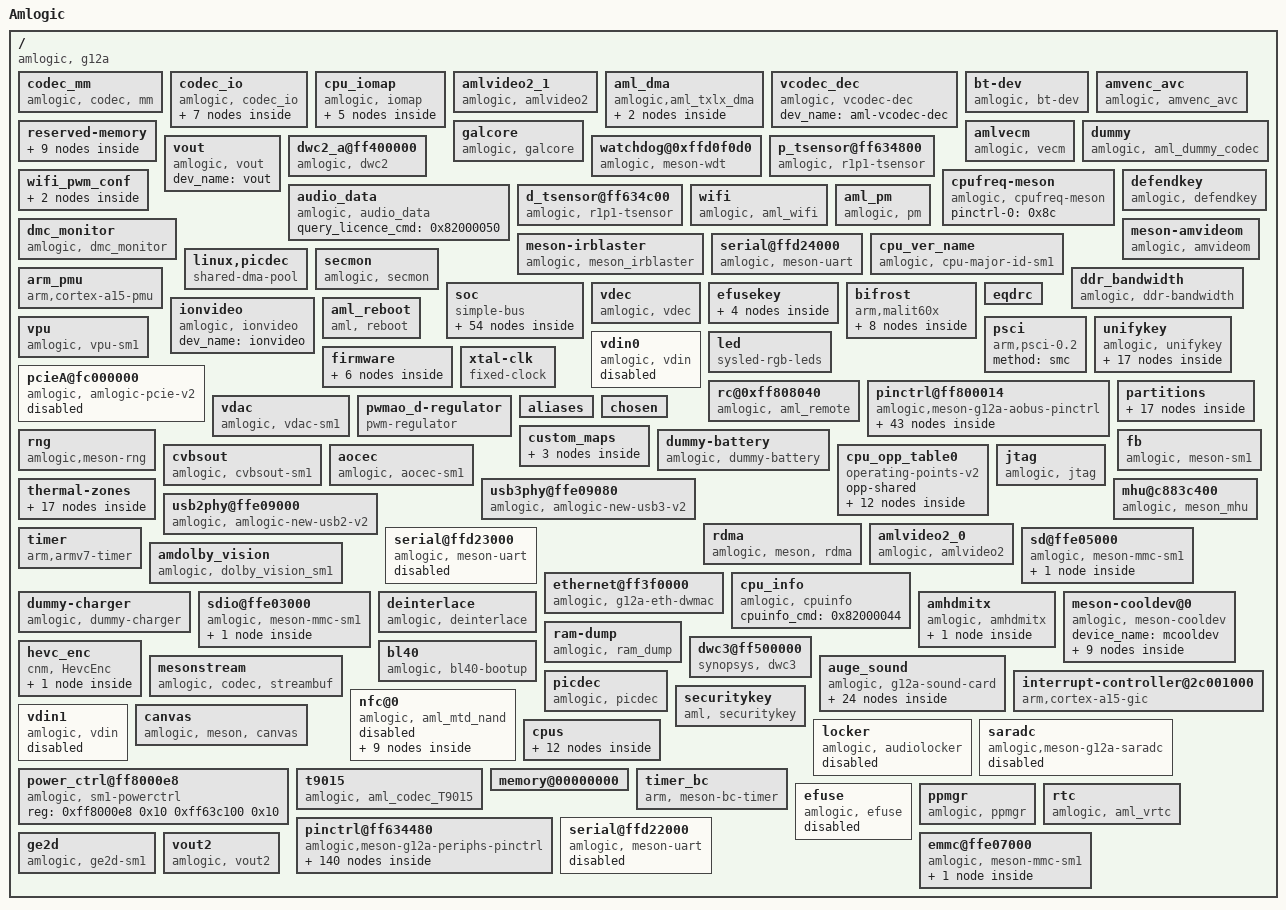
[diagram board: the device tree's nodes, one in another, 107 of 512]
<stdout>: Warning (unit_address_vs_reg): /codec_io/io_efuse_base: node has a reg or ranges property, but no unit name
<stdout>: Warning (unit_address_vs_reg): /codec_io/io_cbus_base: node has a reg or ranges property, but no unit name
<stdout>: Warning (unit_address_vs_reg): /codec_io/io_dmc_base: node has a reg or ranges property, but no unit name
<stdout>: Warning (unit_address_vs_reg): /codec_io/io_vcbus_base: node has a reg or ranges property, but no unit name
<stdout>: Warning (unit_address_vs_reg): /codec_io/io_hiubus_base: node has a reg or ranges property, but no unit name
<stdout>: Warning (unit_address_vs_reg): /codec_io/io_aobus_base: node has a reg or ranges property, but no unit name
<stdout>: Warning (unit_address_vs_reg): /codec_io/io_dos_base: node has a reg or ranges property, but no unit name
<stdout>: Warning (unit_address_vs_reg): /cpu_iomap/io_apb_base: node has a reg or ranges property, but no unit name
<stdout>: Warning (unit_address_vs_reg): /cpu_iomap/io_cbus_base: node has a reg or ranges property, but no unit name
<stdout>: Warning (unit_address_vs_reg): /cpu_iomap/io_vapb_base: node has a reg or ranges property, but no unit name
<stdout>: Warning (unit_address_vs_reg): /cpu_iomap/io_aobus_base: node has a reg or ranges property, but no unit name
<stdout>: Warning (unit_address_vs_reg): /cpu_iomap/io_hiu_base: node has a reg or ranges property, but no unit name
<stdout>: Warning (unit_address_vs_reg): /aml_dma: node has a reg or ranges property, but no unit name
<stdout>: Warning (unit_address_vs_reg): /reserved-memory/linux,secos: node has a reg or ranges property, but no unit name
<stdout>: Warning (unit_address_vs_reg): /galcore: node has a reg or ranges property, but no unit name
<stdout>: Warning (unit_address_vs_reg): /defendkey: node has a reg or ranges property, but no unit name
<stdout>: Warning (unit_address_vs_reg): /meson-irblaster: node has a reg or ranges property, but no unit name
<stdout>: Warning (unit_address_vs_reg): /ddr_bandwidth: node has a reg or ranges property, but no unit name
<stdout>: Warning (unit_address_vs_reg): /arm_pmu: node has a reg or ranges property, but no unit name
<stdout>: Warning (unit_address_vs_reg): /soc/aobus@ff800000/cpu_version: node has a reg or ranges property, but no unit name
<stdout>: Warning (unit_address_vs_reg): /soc/audiobus@0xFF660000/tdm@0: node has a unit name, but no reg or ranges property
<stdout>: Warning (unit_address_vs_reg): /soc/audiobus@0xFF660000/spdif@1: node has a unit name, but no reg or ranges property
<stdout>: Warning (unit_address_vs_reg): /soc/audiobus@0xFF660000/loopback@1: node has a unit name, but no reg or ranges property
<stdout>: Warning (unit_address_vs_reg): /soc/audiobus@0xFF660000/resample@0: node has a unit name, but no reg or ranges property
<stdout>: Warning (unit_address_vs_reg): /soc/audiobus@0xFF660000/tdm@3: node has a unit name, but no reg or ranges property
<stdout>: Warning (unit_address_vs_reg): /soc/audiobus@0xFF660000/tdm@1: node has a unit name, but no reg or ranges property
<stdout>: Warning (unit_address_vs_reg): /soc/audiobus@0xFF660000/audio_clocks: node has a reg or ranges property, but no unit name
<stdout>: Warning (unit_address_vs_reg): /soc/audiobus@0xFF660000/spdif@0: node has a unit name, but no reg or ranges property
<stdout>: Warning (unit_address_vs_reg): /soc/audiobus@0xFF660000/loopback@0: node has a unit name, but no reg or ranges property
<stdout>: Warning (unit_address_vs_reg): /soc/audiobus@0xFF660000/tdm@2: node has a unit name, but no reg or ranges property
<stdout>: Warning (unit_address_vs_reg): /soc/aml_snd_iomap/resampleB_base: node has a reg or ranges property, but no unit name
<stdout>: Warning (unit_address_vs_reg): /soc/aml_snd_iomap/reset_base: node has a reg or ranges property, but no unit name
<stdout>: Warning (unit_address_vs_reg): /soc/aml_snd_iomap/pdm_bus: node has a reg or ranges property, but no unit name
<stdout>: Warning (unit_address_vs_reg): /soc/aml_snd_iomap/resampleA_base: node has a reg or ranges property, but no unit name
<stdout>: Warning (unit_address_vs_reg): /soc/aml_snd_iomap/vad_base: node has a reg or ranges property, but no unit name
<stdout>: Warning (unit_address_vs_reg): /soc/aml_snd_iomap/eqdrc_base: node has a reg or ranges property, but no unit name
<stdout>: Warning (unit_address_vs_reg): /soc/aml_snd_iomap/audiolocker_base: node has a reg or ranges property, but no unit name
<stdout>: Warning (unit_address_vs_reg): /soc/aml_snd_iomap/audiobus_base: node has a reg or ranges property, but no unit name
<stdout>: Warning (unit_address_vs_reg): /soc/cbus@ffd00000/meson_clk_msr: node has a reg or ranges property, but no unit name
<stdout>: Warning (unit_address_vs_reg): /bifrost: node has a reg or ranges property, but no unit name
<stdout>: Warning (unit_address_vs_reg): /pinctrl@ff800014: node has a unit name, but no reg or ranges property
<stdout>: Warning (unit_address_vs_reg): /rng: node has a reg or ranges property, but no unit name
<stdout>: Warning (unit_address_vs_reg): /aocec: node has a reg or ranges property, but no unit name
<stdout>: Warning (unit_address_vs_reg): /thermal-zones/ddr_thermal/trips/trip-point@3: node has a unit name, but no reg or ranges property
<stdout>: Warning (unit_address_vs_reg): /thermal-zones/ddr_thermal/trips/trip-point@1: node has a unit name, but no reg or ranges property
<stdout>: Warning (unit_address_vs_reg): /thermal-zones/ddr_thermal/trips/trip-point@2: node has a unit name, but no reg or ranges property
<stdout>: Warning (unit_address_vs_reg): /thermal-zones/ddr_thermal/trips/trip-point@0: node has a unit name, but no reg or ranges property
<stdout>: Warning (unit_address_vs_reg): /thermal-zones/soc_thermal/trips/trip-point@3: node has a unit name, but no reg or ranges property
<stdout>: Warning (unit_address_vs_reg): /thermal-zones/soc_thermal/trips/trip-point@1: node has a unit name, but no reg or ranges property
<stdout>: Warning (unit_address_vs_reg): /thermal-zones/soc_thermal/trips/trip-point@2: node has a unit name, but no reg or ranges property
<stdout>: Warning (unit_address_vs_reg): /thermal-zones/soc_thermal/trips/trip-point@0: node has a unit name, but no reg or ranges property
<stdout>: Warning (unit_address_vs_reg): /meson-cooldev@0: node has a unit name, but no reg or ranges property
<stdout>: Warning (unit_address_vs_reg): /ram-dump: node has a reg or ranges property, but no unit name
<stdout>: Warning (unit_address_vs_reg): /hevc_enc/io_reg_base: node has a reg or ranges property, but no unit name
<stdout>: Warning (unit_address_vs_reg): /auge_sound/aml-audio-card,dai-link@0: node has a unit name, but no reg or ranges property
<stdout>: Warning (unit_address_vs_reg): /auge_sound/aml-audio-card,dai-link@7: node has a unit name, but no reg or ranges property
<stdout>: Warning (unit_address_vs_reg): /auge_sound/aml-audio-card,dai-link@5: node has a unit name, but no reg or ranges property
<stdout>: Warning (unit_address_vs_reg): /auge_sound/aml-audio-card,dai-link@3: node has a unit name, but no reg or ranges property
<stdout>: Warning (unit_address_vs_reg): /auge_sound/aml-audio-card,dai-link@1: node has a unit name, but no reg or ranges property
<stdout>: Warning (unit_address_vs_reg): /auge_sound/aml-audio-card,dai-link@6: node has a unit name, but no reg or ranges property
<stdout>: Warning (unit_address_vs_reg): /auge_sound/aml-audio-card,dai-link@4: node has a unit name, but no reg or ranges property
<stdout>: Warning (unit_address_vs_reg): /auge_sound/aml-audio-card,dai-link@2: node has a unit name, but no reg or ranges property
<stdout>: Warning (unit_address_vs_reg): /canvas: node has a reg or ranges property, but no unit name
<stdout>: Warning (unit_address_vs_reg): /saradc: node has a reg or ranges property, but no unit name
<stdout>: Warning (unit_address_vs_reg): /t9015: node has a reg or ranges property, but no unit name
<stdout>: Warning (unit_address_vs_reg): /timer_bc: node has a reg or ranges property, but no unit name
<stdout>: Warning (unit_address_vs_reg): /pinctrl@ff634480: node has a unit name, but no reg or ranges property
<stdout>: Warning (unit_address_vs_reg): /ge2d: node has a reg or ranges property, but no unit name
<stdout>: Warning (pci_bridge): /pcieA@fc000000: node name is not "pci" or "pcie"
<stdout>: Warning (unit_address_format): Failed prerequisite 'pci_bridge'
<stdout>: Warning (pci_device_reg): Failed prerequisite 'pci_bridge'
<stdout>: Warning (pci_device_bus_num): Failed prerequisite 'pci_bridge'
<stdout>: Warning (simple_bus_reg): /soc/aobus@ff800000/cpu_version: simple-bus unit address format error, expected "220"
<stdout>: Warning (simple_bus_reg): /soc/audiobus@0xFF660000: simple-bus unit address format error, expected "ff660000"
<stdout>: Warning (simple_bus_reg): /soc/audiobus@0xFF660000/tdm@0: missing or empty reg/ranges property
<stdout>: Warning (simple_bus_reg): /soc/audiobus@0xFF660000/pdm: missing or empty reg/ranges property
<stdout>: Warning (simple_bus_reg): /soc/audiobus@0xFF660000/spdif@1: missing or empty reg/ranges property
<stdout>: Warning (simple_bus_reg): /soc/audiobus@0xFF660000/ddr_manager: missing or empty reg/ranges property
<stdout>: Warning (simple_bus_reg): /soc/audiobus@0xFF660000/vad: missing or empty reg/ranges property
<stdout>: Warning (simple_bus_reg): /soc/audiobus@0xFF660000/i2s2hdmi: missing or empty reg/ranges property
<stdout>: Warning (simple_bus_reg): /soc/audiobus@0xFF660000/effect: missing or empty reg/ranges property
<stdout>: Warning (simple_bus_reg): /soc/audiobus@0xFF660000/loopback@1: missing or empty reg/ranges property
<stdout>: Warning (simple_bus_reg): /soc/audiobus@0xFF660000/resample@0: missing or empty reg/ranges property
<stdout>: Warning (simple_bus_reg): /soc/audiobus@0xFF660000/tdm@3: missing or empty reg/ranges property
<stdout>: Warning (simple_bus_reg): /soc/audiobus@0xFF660000/tdm@1: missing or empty reg/ranges property
<stdout>: Warning (simple_bus_reg): /soc/audiobus@0xFF660000/audio_clocks: simple-bus unit address format error, expected "0"
<stdout>: Warning (simple_bus_reg): /soc/audiobus@0xFF660000/spdif@0: missing or empty reg/ranges property
<stdout>: Warning (simple_bus_reg): /soc/audiobus@0xFF660000/loopback@0: missing or empty reg/ranges property
<stdout>: Warning (simple_bus_reg): /soc/audiobus@0xFF660000/tdm@2: missing or empty reg/ranges property
<stdout>: Warning (simple_bus_reg): /soc/ion_dev: missing or empty reg/ranges property
<stdout>: Warning (simple_bus_reg): /soc/aml_snd_iomap: missing or empty reg/ranges property
<stdout>: Warning (simple_bus_reg): /soc/bus@ff663000/earc@0: simple-bus unit address format error, expected "800"
<stdout>: Warning (simple_bus_reg): /soc/cbus@ffd00000/meson_clk_msr: simple-bus unit address format error, expected "18004"
<stdout>: Warning (simple_bus_reg): /soc/hiubus@ff63c000/clock-controller@1: simple-bus unit address format error, expected "0"
<stdout>: Warning (unique_unit_address): /meson-cooldev@0: duplicate unit-address (also used in node /nfc@0)
<stdout>: Warning (unique_unit_address): /soc/audiobus@0xFF660000/spdif@1: duplicate unit-address (also used in node /soc/audiobus@0xFF660000/loopback@1)
<stdout>: Warning (unique_unit_address): /soc/audiobus@0xFF660000/tdm@0: duplicate unit-address (also used in node /soc/audiobus@0xFF660000/resample@0)
<stdout>: Warning (unique_unit_address): /soc/audiobus@0xFF660000/spdif@1: duplicate unit-address (also used in node /soc/audiobus@0xFF660000/tdm@1)
<stdout>: Warning (unique_unit_address): /soc/audiobus@0xFF660000/loopback@1: duplicate unit-address (also used in node /soc/audiobus@0xFF660000/tdm@1)
<stdout>: Warning (unique_unit_address): /soc/audiobus@0xFF660000/tdm@0: duplicate unit-address (also used in node /soc/audiobus@0xFF660000/spdif@0)
<stdout>: Warning (unique_unit_address): /soc/audiobus@0xFF660000/resample@0: duplicate unit-address (also used in node /soc/audiobus@0xFF660000/spdif@0)
<stdout>: Warning (unique_unit_address): /soc/audiobus@0xFF660000/tdm@0: duplicate unit-address (also used in node /soc/audiobus@0xFF660000/loopback@0)
<stdout>: Warning (unique_unit_address): /soc/audiobus@0xFF660000/resample@0: duplicate unit-address (also used in node /soc/audiobus@0xFF660000/loopback@0)
<stdout>: Warning (unique_unit_address): /soc/audiobus@0xFF660000/spdif@0: duplicate unit-address (also used in node /soc/audiobus@0xFF660000/loopback@0)
<stdout>: Warning (clocks_property): /galcore:clocks: cell 0 is not a phandle reference
<stdout>: Warning (clocks_property): /galcore:clocks: cell 2 is not a phandle reference
<stdout>: Warning (clocks_property): /dwc2_a@ff400000:clocks: cell 0 is not a phandle reference
<stdout>: Warning (clocks_property): /dwc2_a@ff400000:clocks: cell 2 is not a phandle reference
<stdout>: Warning (clocks_property): /watchdog@0xffd0f0d0:clocks: cell 0 is not a phandle reference
<stdout>: Warning (clocks_property): /p_tsensor@ff634800:clocks: cell 0 is not a phandle reference
<stdout>: Warning (clocks_property): /d_tsensor@ff634c00:clocks: cell 0 is not a phandle reference
<stdout>: Warning (clocks_property): /serial@ffd24000:clocks: cell 0 is not a phandle reference
<stdout>: Warning (clocks_property): /serial@ffd24000:clocks: cell 1 is not a phandle reference
<stdout>: Warning (clocks_property): /soc/aobus@ff800000/pwm@2000:clocks: cell 0 is not a phandle reference
<stdout>: Warning (clocks_property): /soc/aobus@ff800000/pwm@2000:clocks: cell 1 is not a phandle reference
<stdout>: Warning (clocks_property): /soc/aobus@ff800000/pwm@2000:clocks: cell 2 is not a phandle reference
<stdout>: Warning (clocks_property): /soc/aobus@ff800000/pwm@2000:clocks: cell 3 is not a phandle reference
<stdout>: Warning (clocks_property): /soc/aobus@ff800000/i2c@5000:clocks: cell 0 is not a phandle reference
<stdout>: Warning (clocks_property): /soc/aobus@ff800000/pwm@7000:clocks: cell 0 is not a phandle reference
<stdout>: Warning (clocks_property): /soc/aobus@ff800000/pwm@7000:clocks: cell 1 is not a phandle reference
<stdout>: Warning (clocks_property): /soc/aobus@ff800000/pwm@7000:clocks: cell 2 is not a phandle reference
<stdout>: Warning (clocks_property): /soc/aobus@ff800000/pwm@7000:clocks: cell 3 is not a phandle reference
<stdout>: Warning (clocks_property): /soc/aobus@ff800000/serial@4000:clocks: cell 0 is not a phandle reference
<stdout>: Warning (clocks_property): /soc/aobus@ff800000/serial@3000:clocks: cell 0 is not a phandle reference
<stdout>: Warning (clocks_property): /soc/audiobus@0xFF660000/tdm@0:clocks: cell 0 is not a phandle reference
<stdout>: Warning (clocks_property): /soc/audiobus@0xFF660000/tdm@0:clocks: cell 2 is not a phandle reference
<stdout>: Warning (clocks_property): /soc/audiobus@0xFF660000/pdm:clocks: cell 0 is not a phandle reference
<stdout>: Warning (clocks_property): /soc/audiobus@0xFF660000/pdm:clocks: cell 2 is not a phandle reference
<stdout>: Warning (clocks_property): /soc/audiobus@0xFF660000/pdm:clocks: cell 4 is not a phandle reference
<stdout>: Warning (clocks_property): /soc/audiobus@0xFF660000/pdm:clocks: cell 6 is not a phandle reference
<stdout>: Warning (clocks_property): /soc/audiobus@0xFF660000/pdm:clocks: cell 8 is not a phandle reference
<stdout>: Warning (clocks_property): /soc/audiobus@0xFF660000/spdif@1:clocks: cell 0 is not a phandle reference
<stdout>: Warning (clocks_property): /soc/audiobus@0xFF660000/spdif@1:clocks: cell 2 is not a phandle reference
<stdout>: Warning (clocks_property): /soc/audiobus@0xFF660000/spdif@1:clocks: cell 4 is not a phandle reference
<stdout>: Warning (clocks_property): /soc/audiobus@0xFF660000/vad:clocks: cell 0 is not a phandle reference
<stdout>: Warning (clocks_property): /soc/audiobus@0xFF660000/vad:clocks: cell 2 is not a phandle reference
<stdout>: Warning (clocks_property): /soc/audiobus@0xFF660000/vad:clocks: cell 4 is not a phandle reference
<stdout>: Warning (clocks_property): /soc/audiobus@0xFF660000/i2s2hdmi:clocks: cell 0 is not a phandle reference
<stdout>: Warning (clocks_property): /soc/audiobus@0xFF660000/i2s2hdmi:clocks: cell 2 is not a phandle reference
<stdout>: Warning (clocks_property): /soc/audiobus@0xFF660000/effect:clocks: cell 0 is not a phandle reference
<stdout>: Warning (clocks_property): /soc/audiobus@0xFF660000/effect:clocks: cell 2 is not a phandle reference
<stdout>: Warning (clocks_property): /soc/audiobus@0xFF660000/effect:clocks: cell 4 is not a phandle reference
<stdout>: Warning (clocks_property): /soc/audiobus@0xFF660000/loopback@1:clocks: cell 0 is not a phandle reference
<stdout>: Warning (clocks_property): /soc/audiobus@0xFF660000/loopback@1:clocks: cell 2 is not a phandle reference
<stdout>: Warning (clocks_property): /soc/audiobus@0xFF660000/loopback@1:clocks: cell 4 is not a phandle reference
<stdout>: Warning (clocks_property): /soc/audiobus@0xFF660000/loopback@1:clocks: cell 6 is not a phandle reference
<stdout>: Warning (clocks_property): /soc/audiobus@0xFF660000/loopback@1:clocks: cell 8 is not a phandle reference
<stdout>: Warning (clocks_property): /soc/audiobus@0xFF660000/loopback@1:clocks: cell 10 is not a phandle reference
<stdout>: Warning (clocks_property): /soc/audiobus@0xFF660000/loopback@1:clocks: cell 12 is not a phandle reference
<stdout>: Warning (clocks_property): /soc/audiobus@0xFF660000/resample@0:clocks: cell 0 is not a phandle reference
<stdout>: Warning (clocks_property): /soc/audiobus@0xFF660000/resample@0:clocks: cell 2 is not a phandle reference
<stdout>: Warning (clocks_property): /soc/audiobus@0xFF660000/resample@0:clocks: cell 4 is not a phandle reference
<stdout>: Warning (clocks_property): /soc/audiobus@0xFF660000/tdm@3:clocks: cell 0 is not a phandle reference
<stdout>: Warning (clocks_property): /soc/audiobus@0xFF660000/tdm@3:clocks: cell 2 is not a phandle reference
<stdout>: Warning (clocks_property): /soc/audiobus@0xFF660000/tdm@1:clocks: cell 0 is not a phandle reference
<stdout>: Warning (clocks_property): /soc/audiobus@0xFF660000/tdm@1:clocks: cell 2 is not a phandle reference
<stdout>: Warning (clocks_property): /soc/audiobus@0xFF660000/tdm@1:clocks: cell 4 is not a phandle reference
<stdout>: Warning (clocks_property): /soc/audiobus@0xFF660000/tdm@1:clocks: cell 6 is not a phandle reference
<stdout>: Warning (clocks_property): /soc/audiobus@0xFF660000/spdif@0:clocks: cell 0 is not a phandle reference
<stdout>: Warning (clocks_property): /soc/audiobus@0xFF660000/spdif@0:clocks: cell 2 is not a phandle reference
<stdout>: Warning (clocks_property): /soc/audiobus@0xFF660000/spdif@0:clocks: cell 4 is not a phandle reference
<stdout>: Warning (clocks_property): /soc/audiobus@0xFF660000/spdif@0:clocks: cell 6 is not a phandle reference
<stdout>: Warning (clocks_property): /soc/audiobus@0xFF660000/spdif@0:clocks: cell 8 is not a phandle reference
<stdout>: Warning (clocks_property): /soc/audiobus@0xFF660000/spdif@0:clocks: cell 10 is not a phandle reference
<stdout>: Warning (clocks_property): /soc/audiobus@0xFF660000/loopback@0:clocks: cell 0 is not a phandle reference
<stdout>: Warning (clocks_property): /soc/audiobus@0xFF660000/loopback@0:clocks: cell 2 is not a phandle reference
<stdout>: Warning (clocks_property): /soc/audiobus@0xFF660000/loopback@0:clocks: cell 4 is not a phandle reference
<stdout>: Warning (clocks_property): /soc/audiobus@0xFF660000/loopback@0:clocks: cell 6 is not a phandle reference
<stdout>: Warning (clocks_property): /soc/audiobus@0xFF660000/loopback@0:clocks: cell 8 is not a phandle reference
<stdout>: Warning (clocks_property): /soc/audiobus@0xFF660000/loopback@0:clocks: cell 10 is not a phandle reference
<stdout>: Warning (clocks_property): /soc/audiobus@0xFF660000/loopback@0:clocks: cell 12 is not a phandle reference
<stdout>: Warning (clocks_property): /soc/audiobus@0xFF660000/tdm@2:clocks: cell 0 is not a phandle reference
<stdout>: Warning (clocks_property): /soc/audiobus@0xFF660000/tdm@2:clocks: cell 2 is not a phandle reference
<stdout>: Warning (clocks_property): /soc/bus@ff663000/earc@0:clocks: cell 0 is not a phandle reference
<stdout>: Warning (clocks_property): /soc/bus@ff663000/earc@0:clocks: cell 2 is not a phandle reference
<stdout>: Warning (clocks_property): /soc/bus@ff663000/earc@0:clocks: cell 4 is not a phandle reference
<stdout>: Warning (clocks_property): /soc/bus@ff663000/earc@0:clocks: cell 6 is not a phandle reference
<stdout>: Warning (clocks_property): /soc/bus@ff663000/earc@0:clocks: cell 8 is not a phandle reference
<stdout>: Warning (clocks_property): /soc/bus@ff663000/earc@0:clocks: cell 10 is not a phandle reference
<stdout>: Warning (clocks_property): /soc/bus@ff663000/earc@0:clocks: cell 12 is not a phandle reference
<stdout>: Warning (clocks_property): /soc/bus@ff663000/earc@0:clocks: cell 14 is not a phandle reference
<stdout>: Warning (clocks_property): /soc/cbus@ffd00000/pwm@1b000:clocks: cell 0 is not a phandle reference
<stdout>: Warning (clocks_property): /soc/cbus@ffd00000/pwm@1b000:clocks: cell 1 is not a phandle reference
<stdout>: Warning (clocks_property): /soc/cbus@ffd00000/pwm@1b000:clocks: cell 2 is not a phandle reference
<stdout>: Warning (clocks_property): /soc/cbus@ffd00000/pwm@1b000:clocks: cell 3 is not a phandle reference
<stdout>: Warning (clocks_property): /soc/cbus@ffd00000/i2c@1d000:clocks: cell 0 is not a phandle reference
<stdout>: Warning (clocks_property): /soc/cbus@ffd00000/pwm@1a000:clocks: cell 0 is not a phandle reference
<stdout>: Warning (clocks_property): /soc/cbus@ffd00000/pwm@1a000:clocks: cell 1 is not a phandle reference
<stdout>: Warning (clocks_property): /soc/cbus@ffd00000/pwm@1a000:clocks: cell 2 is not a phandle reference
<stdout>: Warning (clocks_property): /soc/cbus@ffd00000/pwm@1a000:clocks: cell 3 is not a phandle reference
<stdout>: Warning (clocks_property): /soc/cbus@ffd00000/spi@13000:clocks: cell 0 is not a phandle reference
<stdout>: Warning (clocks_property): /soc/cbus@ffd00000/spi@13000:clocks: cell 2 is not a phandle reference
<stdout>: Warning (clocks_property): /soc/cbus@ffd00000/i2c@1f000:clocks: cell 0 is not a phandle reference
<stdout>: Warning (clocks_property): /soc/cbus@ffd00000/i2c@1c000:clocks: cell 0 is not a phandle reference
<stdout>: Warning (clocks_property): /soc/cbus@ffd00000/spi@15000:clocks: cell 0 is not a phandle reference
<stdout>: Warning (clocks_property): /soc/cbus@ffd00000/spi@15000:clocks: cell 2 is not a phandle reference
<stdout>: Warning (clocks_property): /soc/cbus@ffd00000/i2c@1e000:clocks: cell 0 is not a phandle reference
<stdout>: Warning (clocks_property): /soc/cbus@ffd00000/pwm@19000:clocks: cell 0 is not a phandle reference
<stdout>: Warning (clocks_property): /soc/cbus@ffd00000/pwm@19000:clocks: cell 1 is not a phandle reference
<stdout>: Warning (clocks_property): /soc/cbus@ffd00000/pwm@19000:clocks: cell 2 is not a phandle reference
<stdout>: Warning (clocks_property): /soc/cbus@ffd00000/pwm@19000:clocks: cell 3 is not a phandle reference
<stdout>: Warning (clocks_property): /soc/hiubus@ff63c000/clock-controller@1:clocks: cell 0 is not a phandle reference
<stdout>: Warning (clocks_property): /bifrost:clocks: cell 0 is not a phandle reference
<stdout>: Warning (clocks_property): /bifrost:clocks: cell 2 is not a phandle reference
<stdout>: Warning (clocks_property): /vpu:clocks: cell 0 is not a phandle reference
<stdout>: Warning (clocks_property): /vpu:clocks: cell 2 is not a phandle reference
<stdout>: Warning (clocks_property): /vpu:clocks: cell 4 is not a phandle reference
<stdout>: Warning (clocks_property): /vpu:clocks: cell 6 is not a phandle reference
<stdout>: Warning (clocks_property): /vpu:clocks: cell 8 is not a phandle reference
<stdout>: Warning (clocks_property): /pcieA@fc000000:clocks: cell 0 is not a phandle reference
<stdout>: Warning (clocks_property): /pcieA@fc000000:clocks: cell 2 is not a phandle reference
<stdout>: Warning (clocks_property): /pcieA@fc000000:clocks: cell 4 is not a phandle reference
<stdout>: Warning (clocks_property): /fb:clocks: cell 0 is not a phandle reference
<stdout>: Warning (clocks_property): /cvbsout:clocks: cell 0 is not a phandle reference
<stdout>: Warning (clocks_property): /cvbsout:clocks: cell 2 is not a phandle reference
<stdout>: Warning (clocks_property): /cvbsout:clocks: cell 4 is not a phandle reference
<stdout>: Warning (clocks_property): /cvbsout:clocks: cell 6 is not a phandle reference
<stdout>: Warning (clocks_property): /usb3phy@ffe09080:clocks: cell 0 is not a phandle reference
<stdout>: Warning (clocks_property): /serial@ffd23000:clocks: cell 0 is not a phandle reference
<stdout>: Warning (clocks_property): /serial@ffd23000:clocks: cell 1 is not a phandle reference
<stdout>: Warning (clocks_property): /sd@ffe05000:clocks: cell 0 is not a phandle reference
<stdout>: Warning (clocks_property): /sd@ffe05000:clocks: cell 2 is not a phandle reference
<stdout>: Warning (clocks_property): /sd@ffe05000:clocks: cell 4 is not a phandle reference
<stdout>: Warning (clocks_property): /sd@ffe05000:clocks: cell 6 is not a phandle reference
<stdout>: Warning (clocks_property): /sd@ffe05000:clocks: cell 8 is not a phandle reference
<stdout>: Warning (clocks_property): /ethernet@ff3f0000:clocks: cell 0 is not a phandle reference
<stdout>: Warning (clocks_property): /sdio@ffe03000:clocks: cell 0 is not a phandle reference
<stdout>: Warning (clocks_property): /sdio@ffe03000:clocks: cell 2 is not a phandle reference
<stdout>: Warning (clocks_property): /sdio@ffe03000:clocks: cell 4 is not a phandle reference
<stdout>: Warning (clocks_property): /sdio@ffe03000:clocks: cell 6 is not a phandle reference
<stdout>: Warning (clocks_property): /sdio@ffe03000:clocks: cell 8 is not a phandle reference
<stdout>: Warning (clocks_property): /deinterlace:clocks: cell 0 is not a phandle reference
<stdout>: Warning (clocks_property): /deinterlace:clocks: cell 2 is not a phandle reference
<stdout>: Warning (clocks_property): /amhdmitx:clocks: cell 0 is not a phandle reference
<stdout>: Warning (clocks_property): /amhdmitx:clocks: cell 2 is not a phandle reference
<stdout>: Warning (clocks_property): /amhdmitx:clocks: cell 4 is not a phandle reference
<stdout>: Warning (clocks_property): /amhdmitx:clocks: cell 6 is not a phandle reference
<stdout>: Warning (clocks_property): /amhdmitx:clocks: cell 8 is not a phandle reference
<stdout>: Warning (clocks_property): /dwc3@ff500000:clocks: cell 0 is not a phandle reference
<stdout>: Warning (clocks_property): /mesonstream:clocks: cell 0 is not a phandle reference
<stdout>: Warning (clocks_property): /mesonstream:clocks: cell 2 is not a phandle reference
<stdout>: Warning (clocks_property): /mesonstream:clocks: cell 4 is not a phandle reference
<stdout>: Warning (clocks_property): /mesonstream:clocks: cell 6 is not a phandle reference
<stdout>: Warning (clocks_property): /mesonstream:clocks: cell 8 is not a phandle reference
<stdout>: Warning (clocks_property): /mesonstream:clocks: cell 10 is not a phandle reference
<stdout>: Warning (clocks_property): /mesonstream:clocks: cell 12 is not a phandle reference
<stdout>: Warning (clocks_property): /mesonstream:clocks: cell 14 is not a phandle reference
<stdout>: Warning (clocks_property): /mesonstream:clocks: cell 16 is not a phandle reference
<stdout>: Warning (clocks_property): /nfc@0:clocks: cell 0 is not a phandle reference
<stdout>: Warning (clocks_property): /nfc@0:clocks: cell 2 is not a phandle reference
<stdout>: Warning (clocks_property): /locker:clocks: cell 0 is not a phandle reference
<stdout>: Warning (clocks_property): /locker:clocks: cell 2 is not a phandle reference
<stdout>: Warning (clocks_property): /locker:clocks: cell 4 is not a phandle reference
<stdout>: Warning (clocks_property): /locker:clocks: cell 6 is not a phandle reference
<stdout>: Warning (clocks_property): /locker:clocks: cell 8 is not a phandle reference
<stdout>: Warning (clocks_property): /locker:clocks: cell 10 is not a phandle reference
<stdout>: Warning (clocks_property): /cpus/cpu@3:clocks: cell 0 is not a phandle reference
<stdout>: Warning (clocks_property): /cpus/cpu@3:clocks: cell 2 is not a phandle reference
<stdout>: Warning (clocks_property): /cpus/cpu@3:clocks: cell 4 is not a phandle reference
<stdout>: Warning (clocks_property): /cpus/cpu@3:clocks: cell 6 is not a phandle reference
<stdout>: Warning (clocks_property): /cpus/cpu@3:clocks: cell 8 is not a phandle reference
<stdout>: Warning (clocks_property): /cpus/cpu@1:clocks: cell 0 is not a phandle reference
<stdout>: Warning (clocks_property): /cpus/cpu@1:clocks: cell 2 is not a phandle reference
<stdout>: Warning (clocks_property): /cpus/cpu@1:clocks: cell 4 is not a phandle reference
<stdout>: Warning (clocks_property): /cpus/cpu@1:clocks: cell 6 is not a phandle reference
<stdout>: Warning (clocks_property): /cpus/cpu@1:clocks: cell 8 is not a phandle reference
<stdout>: Warning (clocks_property): /cpus/cpu@2:clocks: cell 0 is not a phandle reference
<stdout>: Warning (clocks_property): /cpus/cpu@2:clocks: cell 2 is not a phandle reference
<stdout>: Warning (clocks_property): /cpus/cpu@2:clocks: cell 4 is not a phandle reference
<stdout>: Warning (clocks_property): /cpus/cpu@2:clocks: cell 6 is not a phandle reference
<stdout>: Warning (clocks_property): /cpus/cpu@2:clocks: cell 8 is not a phandle reference
<stdout>: Warning (clocks_property): /cpus/cpu@0:clocks: cell 0 is not a phandle reference
<stdout>: Warning (clocks_property): /cpus/cpu@0:clocks: cell 2 is not a phandle reference
<stdout>: Warning (clocks_property): /cpus/cpu@0:clocks: cell 4 is not a phandle reference
<stdout>: Warning (clocks_property): /cpus/cpu@0:clocks: cell 6 is not a phandle reference
<stdout>: Warning (clocks_property): /cpus/cpu@0:clocks: cell 8 is not a phandle reference
<stdout>: Warning (clocks_property): /saradc:clocks: cell 0 is not a phandle reference
<stdout>: Warning (clocks_property): /saradc:clocks: cell 1 is not a phandle reference
<stdout>: Warning (clocks_property): /efuse:clocks: cell 0 is not a phandle reference
<stdout>: Warning (clocks_property): /serial@ffd22000:clocks: cell 0 is not a phandle reference
<stdout>: Warning (clocks_property): /serial@ffd22000:clocks: cell 1 is not a phandle reference
<stdout>: Warning (clocks_property): /ge2d:clocks: cell 0 is not a phandle reference
<stdout>: Warning (clocks_property): /ge2d:clocks: cell 2 is not a phandle reference
<stdout>: Warning (clocks_property): /ge2d:clocks: cell 4 is not a phandle reference
<stdout>: Warning (clocks_property): /emmc@ffe07000:clocks: cell 0 is not a phandle reference
<stdout>: Warning (clocks_property): /emmc@ffe07000:clocks: cell 2 is not a phandle reference
<stdout>: Warning (clocks_property): /emmc@ffe07000:clocks: cell 4 is not a phandle reference
<stdout>: Warning (clocks_property): /emmc@ffe07000:clocks: cell 6 is not a phandle reference
<stdout>: Warning (clocks_property): /emmc@ffe07000:clocks: cell 8 is not a phandle reference
<stdout>: Warning (clocks_property): /vout2:clocks: cell 0 is not a phandle reference
<stdout>: Warning (clocks_property): /vout2:clocks: cell 2 is not a phandle reference
<stdout>: Warning (cooling_device_property): /thermal-zones/soc_thermal/cooling-maps/cpufreq_cooling_map:cooling-device: cell 0 is not a phandle reference
<stdout>: Warning (cooling_device_property): /thermal-zones/soc_thermal/cooling-maps/gpucore_cooling_map:cooling-device: cell 0 is not a phandle reference
<stdout>: Warning (cooling_device_property): /thermal-zones/soc_thermal/cooling-maps/cpucore_cooling_map:cooling-device: cell 0 is not a phandle reference
<stdout>: Warning (cooling_device_property): /thermal-zones/soc_thermal/cooling-maps/gpufreq_cooling_map:cooling-device: cell 0 is not a phandle reference
<stdout>: Warning (mboxes_property): /mhu@c883c400:mboxes: cell 0 is not a phandle reference
<stdout>: Warning (mboxes_property): /mhu@c883c400:mboxes: cell 2 is not a phandle reference
<stdout>: Warning (pwms_property): /wifi_pwm_conf/pwm_channel2_conf:pwms: cell 0 is not a phandle reference
<stdout>: Warning (pwms_property): /wifi_pwm_conf/pwm_channel1_conf:pwms: cell 0 is not a phandle reference
<stdout>: Warning (pwms_property): /pwmao_d-regulator:pwms: cell 0 is not a phandle reference
<stdout>: Warning (sound_dai_property): /auge_sound/aml-audio-card,dai-link@0/cpu:sound-dai: cell 0 is not a phandle reference
<stdout>: Warning (sound_dai_property): /auge_sound/aml-audio-card,dai-link@0/codec:sound-dai: cell 0 is not a phandle reference
<stdout>: Warning (sound_dai_property): /auge_sound/aml-audio-card,dai-link@0/codec:sound-dai: cell 1 is not a phandle reference
<stdout>: Warning (sound_dai_property): /auge_sound/aml-audio-card,dai-link@7/cpu:sound-dai: cell 0 is not a phandle reference
<stdout>: Warning (sound_dai_property): /auge_sound/aml-audio-card,dai-link@7/codec:sound-dai: cell 0 is not a phandle reference
<stdout>: Warning (sound_dai_property): /auge_sound/aml-audio-card,dai-link@5/cpu:sound-dai: cell 0 is not a phandle reference
<stdout>: Warning (sound_dai_property): /auge_sound/aml-audio-card,dai-link@5/codec:sound-dai: cell 0 is not a phandle reference
<stdout>: Warning (sound_dai_property): /auge_sound/aml-audio-card,dai-link@3/cpu:sound-dai: cell 0 is not a phandle reference
<stdout>: Warning (sound_dai_property): /auge_sound/aml-audio-card,dai-link@3/codec:sound-dai: cell 0 is not a phandle reference
<stdout>: Warning (sound_dai_property): /auge_sound/aml-audio-card,dai-link@1/cpu:sound-dai: cell 0 is not a phandle reference
<stdout>: Warning (sound_dai_property): /auge_sound/aml-audio-card,dai-link@1/codec:sound-dai: cell 0 is not a phandle reference
<stdout>: Warning (sound_dai_property): /auge_sound/aml-audio-card,dai-link@1/codec:sound-dai: cell 1 is not a phandle reference
<stdout>: Warning (sound_dai_property): /auge_sound/aml-audio-card,dai-link@1/codec:sound-dai: cell 2 is not a phandle reference
<stdout>: Warning (sound_dai_property): /auge_sound/aml-audio-card,dai-link@6/cpu:sound-dai: cell 0 is not a phandle reference
<stdout>: Warning (sound_dai_property): /auge_sound/aml-audio-card,dai-link@6/codec:sound-dai: cell 0 is not a phandle reference
<stdout>: Warning (sound_dai_property): /auge_sound/aml-audio-card,dai-link@4/cpu:sound-dai: cell 0 is not a phandle reference
<stdout>: Warning (sound_dai_property): /auge_sound/aml-audio-card,dai-link@4/codec:sound-dai: cell 0 is not a phandle reference
<stdout>: Warning (sound_dai_property): /auge_sound/aml-audio-card,dai-link@2/cpu:sound-dai: cell 0 is not a phandle reference
<stdout>: Warning (sound_dai_property): /auge_sound/aml-audio-card,dai-link@2/codec:sound-dai: cell 0 is not a phandle reference
<stdout>: Warning (sound_dai_property): /auge_sound/aml-audio-card,dai-link@2/codec:sound-dai: cell 1 is not a phandle reference
<stdout>: Warning (thermal_sensors_property): /thermal-zones/ddr_thermal:thermal-sensors: cell 0 is not a phandle reference
<stdout>: Warning (thermal_sensors_property): /thermal-zones/soc_thermal:thermal-sensors: cell 0 is not a phandle reference
<stdout>: Warning (gpios_property): /__symbols__:gpio: property size (33) is invalid, expected multiple of 4
<stdout>: Warning (gpios_property): /led:r-gpios: cell 0 is not a phandle reference
<stdout>: Warning (gpios_property): /led:b-gpios: cell 0 is not a phandle reference
<stdout>: Warning (gpios_property): /pcieA@fc000000:reset-gpio: cell 0 is not a phandle reference
<stdout>: Warning (gpios_property): /usb2phy@ffe09000:gpios: cell 0 is not a phandle reference
<stdout>: Warning (gpios_property): /auge_sound:avout_mute-gpios: cell 0 is not a phandle reference
/dts-v1/;

/ {
	compatible = "amlogic, g12a";
	model = "Amlogic";
	interrupt-parent = <0x01>;
	#address-cells = <0x01>;
	#size-cells = <0x01>;
	amlogic-dt-id = "sm1_X2CUBE_4g";

	codec_mm {
		compatible = "amlogic, codec, mm";
		dev_name = "codec_mm";
		status = "okay";
		memory-region = <0x68 0x69>;
	};

	codec_io {
		compatible = "amlogic, codec_io";
		ranges;
		status = "okay";
		#address-cells = <0x01>;
		#size-cells = <0x01>;
		phandle = <0xf0>;

		io_efuse_base {
			reg = <0xff630000 0x2000>;
		};

		io_cbus_base {
			reg = <0xffd00000 0x100000>;
		};

		io_dmc_base {
			reg = <0xff638000 0x2000>;
		};

		io_vcbus_base {
			reg = <0xff900000 0x40000>;
		};

		io_hiubus_base {
			reg = <0xff63c000 0x2000>;
		};

		io_aobus_base {
			reg = <0xff800000 0x10000>;
		};

		io_dos_base {
			reg = <0xff620000 0x10000>;
		};
	};

	cpu_iomap {
		compatible = "amlogic, iomap";
		ranges;
		#address-cells = <0x01>;
		#size-cells = <0x01>;

		io_apb_base {
			reg = <0xffe01000 0x7f000>;
		};

		io_cbus_base {
			reg = <0xffd00000 0x26fff>;
		};

		io_vapb_base {
			reg = <0xff900000 0x50000>;
		};

		io_aobus_base {
			reg = <0xff800000 0xb000>;
		};

		io_hiu_base {
			reg = <0xff63c000 0x2000>;
		};
	};

	amlvideo2_1 {
		compatible = "amlogic, amlvideo2";
		amlvideo2_id = <0x01>;
		dev_name = "amlvideo2";
		cma_mode = <0x01>;
		status = "okay";
	};

	aml_dma {
		compatible = "amlogic,aml_txlx_dma";
		interrupts = <0x00 0xb4 0x01>;
		reg = <0xff63e000 0x48>;

		aml_sha {
			compatible = "amlogic,sha_dma";
			dev_name = "aml_sha_dma";
			status = "okay";
		};

		aml_aes {
			compatible = "amlogic,aes_g12a_dma";
			dev_name = "aml_aes_dma";
			status = "okay";
		};
	};

	vcodec_dec {
		compatible = "amlogic, vcodec-dec";
		dev_name = "aml-vcodec-dec";
		status = "okay";
	};

	bt-dev {
		compatible = "amlogic, bt-dev";
		dev_name = "bt-dev";
		status = "okay";
		gpio_hostwake = <0x14 0x55 0x00>;
		gpio_reset = <0x14 0x53 0x00>;
	};

	amvenc_avc {
		compatible = "amlogic, amvenc_avc";
		dev_name = "amvenc_avc";
		status = "okay";
		interrupts = <0x00 0x2d 0x01>;
		interrupt-names = "mailbox_2";
	};

	reserved-memory {
		ranges;
		#address-cells = <0x01>;
		#size-cells = <0x01>;

		linux,ion-dev {
			reusable;
			compatible = "shared-dma-pool";
			alignment = <0x400000>;
			alloc-ranges = <0x30000000 0x50000000>;
			size = <0x8000000>;
			phandle = <0x1b>;
		};

		ramoops@0x07400000 {
			compatible = "ramoops";
			record-size = <0x8000>;
			console-size = <0x8000>;
			ftrace-size = <0x40000>;
			reg = <0x7400000 0x100000>;
		};

		linux,meson-fb {
			reusable;
			compatible = "shared-dma-pool";
			alignment = <0x400000>;
			alloc-ranges = <0x7f800000 0x800000>;
			size = <0x800000>;
			phandle = <0x37>;
		};

		linux,ppmgr {
			compatible = "shared-dma-pool";
			size = <0x00>;
			phandle = <0x6b>;
		};

		linux,secos {
			compatible = "amlogic, aml_secos_memory";
			status = "disable";
			no-map;
			phandle = <0x105>;
			reg = <0x5300000 0x2000000>;
		};

		linux,di_cma {
			reusable;
			compatible = "shared-dma-pool";
			alignment = <0x400000>;
			size = <0x2800000>;
			phandle = <0x6c>;
		};

		linux,codec_mm_cma {
			reusable;
			compatible = "shared-dma-pool";
			alignment = <0x400000>;
			alloc-ranges = <0x30000000 0x50000000>;
			size = <0x13400000>;
			phandle = <0x68>;
			linux,contiguous-region;
		};

		linux,secmon {
			reusable;
			compatible = "shared-dma-pool";
			alignment = <0x400000>;
			alloc-ranges = <0x5000000 0x400000>;
			size = <0x400000>;
			phandle = <0x0f>;
		};

		linux,codec_mm_reserved {
			compatible = "amlogic, codec-mm-reserved";
			alignment = <0x100000>;
			size = <0x00>;
			phandle = <0x69>;
		};
	};

	galcore {
		compatible = "amlogic, galcore";
		clocks = <0x02 0xe8 0x02 0xe7>;
		nn_efuse = <0xff63003c 0x20>;
		dev_name = "galcore";
		reg-names = "NN_REG", "NN_SRAM", "NN_MEM0", "NN_MEM1", "NN_RESET", "NN_CLK";
		clock-names = "cts_vipnanoq_axi_clk_composite", "cts_vipnanoq_core_clk_composite";
		status = "okay";
		interrupts = <0x00 0xba 0x04>;
		reg = <0xff100000 0x800 0xff000000 0x400000 0xff63c118 0x00 0xff63c11c 0x00 0xffd01088 0x00 0xff63c1c8 0x00>;
		nn_power_version = <0x03>;
		interrupt-names = "galcore";
	};

	amlvecm {
		compatible = "amlogic, vecm";
		wb_en = <0x00>;
		dev_name = "aml_vecm";
		cm_en = <0x00>;
		status = "okay";
		gamma_en = <0x00>;
		tx_op_color_primary = <0x00>;
	};

	dummy {
		compatible = "amlogic, aml_dummy_codec";
		#sound-dai-cells = <0x00>;
		status = "okay";
		phandle = <0x83>;
	};

	vout {
		compatible = "amlogic, vout";
		dev_name = "vout";
		status = "okay";
	};

	dwc2_a@ff400000 {
		port-type = <0x02>;
		compatible = "amlogic, dwc2";
		port-config = <0x00>;
		clocks = <0x02 0x41 0x02 0x49>;
		port-speed = <0x00>;
		controller-type = <0x03>;
		clock-names = "usb_general", "usb1";
		clock-src = "usb0";
		status = "okay";
		interrupts = <0x00 0x1f 0x04>;
		port-id-mode = <0x00>;
		phandle = <0xc4>;
		phy-interface = <0x02>;
		device_name = "dwc2_a";
		phy-reg = <0xffe09000>;
		usb-fifo = <0x2d8>;
		reg = <0xff400000 0x40000>;
		cpu-type = "v2";
		port-id = <0x00>;
		port-dma = <0x00>;
		pl-periph-id = <0x00>;
		phy-reg-size = <0xa0>;
	};

	watchdog@0xffd0f0d0 {
		compatible = "amlogic, meson-wdt";
		clocks = <0x15>;
		clock-names = "xtal";
		reset_watchdog_time = <0x02>;
		shutdown_timeout = <0x0a>;
		status = "okay";
		suspend_timeout = <0x06>;
		default_timeout = <0x0a>;
		phandle = <0xc5>;
		firmware_timeout = <0x06>;
		reg = <0xffd0f0d0 0x10>;
		reset_watchdog_method = <0x01>;
	};

	p_tsensor@ff634800 {
		compatible = "amlogic, r1p1-tsensor";
		clocks = <0x02 0xd6>;
		cal_d = <0x24c3>;
		#thermal-sensor-cells = <0x01>;
		clock-names = "ts_comp";
		cal_b = <0x1a8>;
		rtemp = <0x1c138>;
		status = "okay";
		interrupts = <0x00 0x23 0x00>;
		phandle = <0x4c>;
		device_name = "meson-pthermal";
		reg = <0xff634800 0x50 0xff800268 0x04>;
		cal_type = <0x01>;
		cal_c = <0xc57>;
		cal_a = <0x144>;
	};

	cpufreq-meson {
		compatible = "amlogic, cpufreq-meson";
		status = "okay";
		pinctrl-0 = <0x8c>;
		pinctrl-names = "default";
	};

	audio_data {
		compatible = "amlogic, audio_data";
		query_licence_cmd = <0x82000050>;
		status = "okay";
		phandle = <0xc2>;
	};

	d_tsensor@ff634c00 {
		compatible = "amlogic, r1p1-tsensor";
		clocks = <0x02 0xd6>;
		cal_d = <0x24c3>;
		#thermal-sensor-cells = <0x01>;
		clock-names = "ts_comp";
		cal_b = <0x1a8>;
		rtemp = <0x1c138>;
		status = "okay";
		interrupts = <0x00 0x24 0x00>;
		phandle = <0x52>;
		device_name = "meson-dthermal";
		reg = <0xff634c00 0x50 0xff800230 0x04>;
		cal_type = <0x01>;
		cal_c = <0xc57>;
		cal_a = <0x144>;
	};

	defendkey {
		compatible = "amlogic, defendkey";
		status = "okay";
		mem_size = <0x00 0x100000>;
		phandle = <0xf7>;
		reg = <0xff630218 0x04>;
	};

	wifi_pwm_conf {
		phandle = <0x66>;

		pwm_channel2_conf {
			times = <0x0c>;
			duty-cycle = <0x3b92>;
			pwms = <0x67 0x02 0x7724 0x00>;
		};

		pwm_channel1_conf {
			times = <0x0a>;
			duty-cycle = <0x3ba6>;
			pwms = <0x67 0x00 0x774d 0x00>;
		};
	};

	wifi {
		pwm_config = <0x66>;
		compatible = "amlogic, aml_wifi";
		interrupt_pin = <0x14 0x49 0x00>;
		dev_name = "aml_wifi";
		status = "okay";
		dhd_static_buf;
		pinctrl-0 = <0x65>;
		power_on_pin = <0x14 0x48 0x00>;
		pinctrl-names = "default";
		irq_trigger_type = "GPIO_IRQ_LOW";
	};

	dmc_monitor {
		compatible = "amlogic, dmc_monitor";
		status = "okay";
		interrupts = <0x00 0x33 0x01>;
		reg_base = <0xff639000>;
	};

	meson-irblaster {
		compatible = "amlogic, meson_irblaster";
		status = "okay";
		interrupts = <0x00 0xc6 0x01>;
		phandle = <0xf2>;
		reg = <0xff80014c 0x10 0xff800040 0x04>;
		pinctrl-0 = <0x38>;
		pinctrl-names = "default";
	};

	meson-amvideom {
		compatible = "amlogic, amvideom";
		dev_name = "amvideom";
		status = "okay";
		interrupts = <0x00 0x03 0x01>;
		interrupt-names = "vsync";
	};

	aml_pm {
		compatible = "amlogic, pm";
		status = "okay";
		device_name = "aml_pm";
		debug_reg = <0xff8000a8>;
		exit_reg = <0xff80023c>;
	};

	serial@ffd24000 {
		compatible = "amlogic, meson-uart";
		clocks = <0x15 0x02 0x2e>;
		fifosize = <0x80>;
		clock-names = "clk_uart", "clk_gate";
		status = "okay";
		interrupts = <0x00 0x1a 0x01>;
		phandle = <0xe7>;
		reg = <0xffd24000 0x18>;
		pinctrl-0 = <0x2d>;
		pinctrl-names = "default";
	};

	cpu_ver_name {
		compatible = "amlogic, cpu-major-id-sm1";
	};

	linux,picdec {
		reusable;
		compatible = "shared-dma-pool";
		alignment = <0x00>;
		size = <0x00>;
		phandle = <0x6a>;
		linux,contiguous-region;
	};

	secmon {
		compatible = "amlogic, secmon";
		in_base_func = <0x82000020>;
		out_base_func = <0x82000021>;
		reserve_mem_size = <0x300000>;
		memory-region = <0x0f>;
	};

	__symbols__ {
		phot = "/thermal-zones/soc_thermal/trips/trip-point@2";
		i2c3 = "/soc/cbus@ffd00000/i2c@1c000";
		sd_emmc_c = "/emmc@ffe07000";
		meson_cooldev = "/meson-cooldev@0";
		pwm_d_pins2 = "/pinctrl@ff634480/pwm_d_pins2";
		pwm_a_pins = "/pinctrl@ff634480/pwm_a";
		vddcpu0 = "/pwmao_d-regulator";
		pdmin = "/pinctrl@ff634480/pdmin";
		amlogic_battery = "/dummy-battery";
		key_2 = "/efusekey/key_2";
		dvfs500_cfg = "/bifrost/dvfs500_cfg";
		dvfs666_cfg = "/bifrost/dvfs666_cfg";
		uart_C = "/serial@ffd22000";
		usb3_phy_v2 = "/usb3phy@ffe09080";
		codec_io = "/codec_io";
		hym8563 = "/soc/cbus@ffd00000/i2c@1c000/hym8563@51";
		spicc1_pins = "/pinctrl@ff634480/spicc1_pins";
		keysn_15 = "/unifykey/key_15";
		i2c1_master_pins1 = "/pinctrl@ff634480/i2c1_pins1";
		logo = "/partitions/logo";
		keysn_6 = "/unifykey/key_6";
		vendor = "/partitions/vendor";
		ao_to_sd_uart_pins = "/pinctrl@ff634480/ao_to_sd_uart_pins";
		sdio_x_clr_pins = "/pinctrl@ff634480/sdio_x_clr_pins";
		emmc_conf_pull_up = "/pinctrl@ff634480/emmc_conf_pull_up";
		dvfs285_cfg = "/bifrost/dvfs285_cfg";
		param = "/partitions/param";
		dvfs800_cfg = "/bifrost/dvfs800_cfg";
		loopbackb = "/soc/audiobus@0xFF660000/loopback@1";
		pdm = "/soc/audiobus@0xFF660000/pdm";
		secmon_reserved = "/reserved-memory/linux,secmon";
		i2c1 = "/soc/cbus@ffd00000/i2c@1e000";
		sd_emmc_a = "/sdio@ffe03000";
		pwm_c_pins3 = "/pinctrl@ff634480/pwm_c_pins3";
		sdio_x_all_pins = "/pinctrl@ff634480/sdio_x_all_pins";
		aml_i2s2hdmi = "/soc/audiobus@0xFF660000/i2s2hdmi";
		key_0 = "/efusekey/key_0";
		power_ctrl = "/power_ctrl@ff8000e8";
		logo_reserved = "/reserved-memory/linux,meson-fb";
		sdio_clk_cmd_pins = "/pinctrl@ff634480/sdio_clk_cmd_pins";
		uart_A = "/serial@ffd24000";
		ao_uart_pins = "/pinctrl@ff800014/ao_uart";
		ao_i2c_master_pins1 = "/pinctrl@ff800014/ao_i2c_pins1";
		tdmout_b = "/pinctrl@ff634480/tdmout_b";
		gpu = "/bifrost";
		keysn_13 = "/unifykey/key_13";
		spdifout = "/pinctrl@ff634480/spdifout";
		audio_data = "/audio_data";
		keysn_4 = "/unifykey/key_4";
		pwm_ef = "/soc/cbus@ffd00000/pwm@19000";
		dcritical = "/thermal-zones/ddr_thermal/trips/trip-point@3";
		pwm_ao_a_hiz_pins = "/pinctrl@ff800014/pwm_ao_a_hiz";
		i2c2_master_pins3 = "/pinctrl@ff634480/i2c2_pins3";
		defendkey = "/defendkey";
		external_eth_pins = "/pinctrl@ff634480/external_eth_pins";
		wifi_pwm_conf = "/wifi_pwm_conf";
		map_1 = "/custom_maps/map_1";
		uart_AO_B = "/soc/aobus@ff800000/serial@4000";
		sd_to_ao_uart_clr_pins = "/pinctrl@ff800014/sd_to_ao_uart_clr_pins";
		jtag_apee_pins = "/pinctrl@ff634480/jtag_apee_pin";
		a_uart_pins = "/pinctrl@ff634480/a_uart";
		periphs = "/soc/periphs@ff634400";
		internal_gpio_pins = "/pinctrl@ff634480/internal_gpio_pins";
		pinctrl_aobus = "/pinctrl@ff800014";
		pswitch_on = "/thermal-zones/soc_thermal/trips/trip-point@0";
		dtbo = "/partitions/dtbo";
		usb2_phy_v2 = "/usb2phy@ffe09000";
		gpio = "/pinctrl@ff634480/banks@ff6346c0";
		pwm_c_pins1 = "/pinctrl@ff634480/pwm_c_pins1";
		pwm_ao_d_pins2 = "/pinctrl@ff800014/pwm_ao_d_pins2";
		emmc_conf_pull_done = "/pinctrl@ff634480/emmc_conf_pull_done";
		amlogic_charger = "/dummy-charger";
		ion_cma_reserved = "/reserved-memory/linux,ion-dev";
		misc = "/partitions/misc";
		tee = "/partitions/tee";
		dvfs250_cfg = "/bifrost/dvfs250_cfg";
		keysn_11 = "/unifykey/key_11";
		clkc_b = "/soc/hiubus@ff63c000/clock-controller@1";
		pwm_f_pins1 = "/pinctrl@ff634480/pwm_f_pins1";
		codec_mm_reserved = "/reserved-memory/linux,codec_mm_reserved";
		keysn_2 = "/unifykey/key_2";
		i2c2_master_pins1 = "/pinctrl@ff634480/i2c2_pins1";
		gpufreq_cool0 = "/meson-cooldev@0/gpufreq_cool0";
		eecec_a = "/pinctrl@ff634480/ee_ceca";
		spicc0 = "/soc/cbus@ffd00000/spi@13000";
		vad = "/soc/audiobus@0xFF660000/vad";
		jtag_apao_pins = "/pinctrl@ff800014/jtag_apao_pin";
		secos_reserved = "/reserved-memory/linux,secos";
		system = "/partitions/system";
		tdmbcodec = "/auge_sound/aml-audio-card,dai-link@1/codec";
		asrca = "/soc/audiobus@0xFF660000/resample@0";
		pwm_b_pins2 = "/pinctrl@ff634480/pwm_b_pins2";
		irblaster_pins = "/pinctrl@ff800014/irblaster_pin";
		i2c0_master_pins2 = "/pinctrl@ff634480/i2c0_pins2";
		pwm_cd = "/soc/cbus@ffd00000/pwm@1a000";
		pcontrol = "/thermal-zones/soc_thermal/trips/trip-point@1";
		dvfs850_cfg = "/bifrost/dvfs850_cfg";
		cbus = "/soc/cbus@ffd00000";
		dhot = "/thermal-zones/ddr_thermal/trips/trip-point@2";
		keysn_0 = "/unifykey/key_0";
		codec_mm_cma = "/reserved-memory/linux,codec_mm_cma";
		p_tsensor = "/p_tsensor@ff634800";
		efusekey = "/efusekey";
		gic = "/interrupt-controller@2c001000";
		tdmb = "/soc/audiobus@0xFF660000/tdm@1";
		audiolocker = "/locker";
		aocec_a = "/pinctrl@ff800014/ao_ceca";
		pdm_codec = "/dummy";
		remote_pins = "/pinctrl@ff800014/remote_pin";
		cri_data = "/partitions/cri_data";
		di_cma_reserved = "/reserved-memory/linux,di_cma";
		vpu = "/vpu";
		picdec_cma_reserved = "/linux,picdec";
		product = "/partitions/product";
		metadata = "/partitions/metadata";
		pwm_ao_c_pins1 = "/pinctrl@ff800014/pwm_ao_c_pins1";
		earc = "/soc/bus@ff663000/earc@0";
		nand_cs_pins = "/pinctrl@ff634480/nand_cs";
		pwm_e_pins = "/pinctrl@ff634480/pwm_e";
		ddr_thermal = "/thermal-zones/ddr_thermal";
		vdin0 = "/vdin0";
		i2c_AO = "/soc/aobus@ff800000/i2c@5000";
		tdmin_c = "/pinctrl@ff634480/tdmin_c";
		keysn_9 = "/unifykey/key_9";
		tdmacpu = "/auge_sound/aml-audio-card,dai-link@0/cpu";
		spdifa = "/soc/audiobus@0xFF660000/spdif@0";
		CPU2 = "/cpus/cpu@2";
		tdmacodec = "/auge_sound/aml-audio-card,dai-link@0/codec";
		partitions = "/partitions";
		pinctrl_periphs = "/pinctrl@ff634480";
		sd_clr_all_pins = "/pinctrl@ff634480/sd_clr_all_pins";
		pwm_ab = "/soc/cbus@ffd00000/pwm@1b000";
		nandnormal = "/nfc@0/nandnormal";
		cpufreq_cool0 = "/meson-cooldev@0/cpufreq_cool0";
		nand = "/nfc@0";
		i2c3_master_pins1 = "/pinctrl@ff634480/i2c3_pins1";
		key_3 = "/efusekey/key_3";
		bootloader = "/nfc@0/bootloader";
		aobus = "/soc/aobus@ff800000";
		custom_maps = "/custom_maps";
		pcie_A = "/pcieA@fc000000";
		clkc = "/soc/hiubus@ff63c000/clock-controller@0";
		all_nand_pins = "/pinctrl@ff634480/all_nand_pins";
		tdmc_mclk = "/pinctrl@ff634480/tdmc_mclk";
		keysn_16 = "/unifykey/key_16";
		pwm_ao_b_pins = "/pinctrl@ff800014/pwm_ao_b";
		i2c1_master_pins2 = "/pinctrl@ff634480/i2c1_pins2";
		tdmin_a = "/pinctrl@ff634480/tdmin_a";
		keysn_7 = "/unifykey/key_7";
		vend_data = "/amhdmitx/vend_data";
		sd_all_pins = "/pinctrl@ff634480/sd_all_pins";
		wdt = "/watchdog@0xffd0f0d0";
		ao_i2c_slave_pins = "/pinctrl@ff800014/ao_i2c_slave_pins";
		vbmeta = "/partitions/vbmeta";
		CPU0 = "/cpus/cpu@0";
		tdmlb = "/soc/audiobus@0xFF660000/tdm@3";
		aocec = "/aocec";
		i2c2 = "/soc/cbus@ffd00000/i2c@1d000";
		sd_emmc_b = "/sd@ffe05000";
		pwm_d_pins1 = "/pinctrl@ff634480/pwm_d_pins1";
		cpu_opp_table0 = "/cpu_opp_table0";
		i2c_AO_slave = "/soc/aobus@ff800000/i2c_slave@6000";
		audiobus = "/soc/audiobus@0xFF660000";
		key_1 = "/efusekey/key_1";
		nand_partitions = "/nfc@0/nand_partition";
		b_uart_pins = "/pinctrl@ff634480/b_uart";
		dummy_codec = "/dummy";
		uart_B = "/serial@ffd23000";
		ao_i2c_master_pins2 = "/pinctrl@ff800014/ao_i2c_pins2";
		sd_all_pd_pins = "/pinctrl@ff634480/sd_all_pd_pins";
		odm = "/partitions/odm";
		tdmout_c = "/pinctrl@ff634480/tdmout_c";
		keysn_14 = "/unifykey/key_14";
		dswitch_on = "/thermal-zones/ddr_thermal/trips/trip-point@0";
		keysn_5 = "/unifykey/key_5";
		spicc0_pins_x = "/pinctrl@ff634480/spicc0_pins_x";
		dcontrol = "/thermal-zones/ddr_thermal/trips/trip-point@1";
		internal_eth_pins = "/pinctrl@ff634480/internal_eth_pins";
		dvfs125_cfg = "/bifrost/clk125_cfg";
		loopbacka = "/soc/audiobus@0xFF660000/loopback@0";
		map_2 = "/custom_maps/map_2";
		sdio_x_en_pins = "/pinctrl@ff634480/sdio_x_en_pins";
		hdmitx_ddc = "/pinctrl@ff634480/hdmitx_ddc";
		gpio_intc = "/soc/cbus@ffd00000/interrupt-controller@f080";
		cache = "/partitions/cache";
		i2c0 = "/soc/cbus@ffd00000/i2c@1f000";
		pwm_c_pins2 = "/pinctrl@ff634480/pwm_c_pins2";
		pwm_ao_d_pins3 = "/pinctrl@ff800014/pwm_ao_d_pins3";
		sd_clk_cmd_pins = "/pinctrl@ff634480/sd_clk_cmd_pins";
		tdmb_mclk = "/pinctrl@ff634480/tdmb_mclk";
		pwm_ao_a_pins = "/pinctrl@ff800014/pwm_ao_a";
		d_tsensor = "/d_tsensor@ff634c00";
		sd_to_ao_uart_pins = "/pinctrl@ff800014/sd_to_ao_uart_pins";
		dvfs400_cfg = "/bifrost/dvfs400_cfg";
		remote = "/rc@0xff808040";
		cluster0 = "/cpus/cpu-map/cluster0";
		CPU_SLEEP_0 = "/cpus/idle-states/cpu-sleep-0";
		amlogic_codec = "/t9015";
		tdmout_a = "/pinctrl@ff634480/tdmout_a";
		keysn_12 = "/unifykey/key_12";
		pwm_f_pins2 = "/pinctrl@ff634480/pwm_f_pins2";
		hiubus = "/soc/hiubus@ff63c000";
		sd_1bit_pins = "/pinctrl@ff634480/sd_1bit_pins";
		keysn_3 = "/unifykey/key_3";
		i2c2_master_pins2 = "/pinctrl@ff634480/i2c2_pins2";
		spicc0_pins_c = "/pinctrl@ff634480/spicc0_pins_c";
		eecec_b = "/pinctrl@ff634480/ee_cecb";
		ppmgr_reserved = "/reserved-memory/linux,ppmgr";
		spicc1 = "/soc/cbus@ffd00000/spi@15000";
		map_0 = "/custom_maps/map_0";
		dwc2_a = "/dwc2_a@ff400000";
		pwm_ao_d_pins1 = "/pinctrl@ff800014/pwm_ao_d_pins1";
		gpucore_cool0 = "/meson-cooldev@0/gpucore_cool0";
		aed = "/soc/audiobus@0xFF660000/effect";
		amhdmitx = "/amhdmitx";
		memory = "/memory@00000000";
		i2c0_master_pins3 = "/pinctrl@ff634480/i2c0_pins3";
		soc_thermal = "/thermal-zones/soc_thermal";
		audio_earc = "/soc/bus@ff663000";
		gpio_ao = "/pinctrl@ff800014/ao-bank@ff800014";
		data = "/partitions/data";
		pwm_ao_c_hiz_pins = "/pinctrl@ff800014/pwm_ao_c_hiz";
		bl40 = "/bl40";
		clkaudio = "/soc/audiobus@0xFF660000/audio_clocks";
		xtal = "/xtal-clk";
		keysn_10 = "/unifykey/key_10";
		keysn_1 = "/unifykey/key_1";
		pwm_AO_cd = "/soc/aobus@ff800000/pwm@2000";
		tdmc = "/soc/audiobus@0xFF660000/tdm@2";
		uart_AO = "/soc/aobus@ff800000/serial@3000";
		aocec_b = "/pinctrl@ff800014/ao_cecb";
		audio_effect = "/eqdrc";
		pwm_b_pins1 = "/pinctrl@ff634480/pwm_b_pins1";
		pwm_ao_c_pins2 = "/pinctrl@ff800014/pwm_ao_c_pins2";
		ethmac = "/ethernet@ff3f0000";
		pcritical = "/thermal-zones/soc_thermal/trips/trip-point@3";
		i2c0_master_pins1 = "/pinctrl@ff634480/i2c0_pins1";
		vdin1 = "/vdin1";
		aoclkc = "/soc/aobus@ff800000/clock-controller@0";
		canvas = "/canvas";
		cpus = "/cpus";
		recovery = "/partitions/recovery";
		spdifb = "/soc/audiobus@0xFF660000/spdif@1";
		saradc = "/saradc";
		sdio_all_pins = "/pinctrl@ff634480/sdio_all_pins";
		sd_clr_noall_pins = "/pinctrl@ff634480/sd_clr_noall_pins";
		CPU3 = "/cpus/cpu@3";
		boot = "/partitions/boot";
		tdma = "/soc/audiobus@0xFF660000/tdm@0";
		spdifout_a_mute = "/pinctrl@ff634480/spdifout_a_mute";
		i2c3_master_pins2 = "/pinctrl@ff634480/i2c3_pins2";
		sdio_x_clk_cmd_pins = "/pinctrl@ff634480/sdio_x_clk_cmd_pins";
		efuse = "/efuse";
		dwc3 = "/dwc3@ff500000";
		irblaster = "/meson-irblaster";
		ao_b_uart_pins = "/pinctrl@ff800014/ao_b_uart";
		mailbox = "/mhu@c883c400";
		cpucore_cool0 = "/meson-cooldev@0/cpucore_cool0";
		c_uart_pins = "/pinctrl@ff634480/c_uart";
		pwm_AO_ab = "/soc/aobus@ff800000/pwm@7000";
		i2c1_master_pins3 = "/pinctrl@ff634480/i2c1_pins3";
		tdmin_b = "/pinctrl@ff634480/tdmin_b";
		keysn_8 = "/unifykey/key_8";
		rsv = "/partitions/rsv";
		hdmitx_hpd = "/pinctrl@ff634480/hdmitx_hpd";
		emmc_clk_cmd_pins = "/pinctrl@ff634480/emmc_clk_cmd_pins";
		meson_fb = "/fb";
		CPU1 = "/cpus/cpu@1";
		hdmitx_hpd_gpio = "/pinctrl@ff634480/hdmitx_hpd_gpio";
	};

	ddr_bandwidth {
		compatible = "amlogic, ddr-bandwidth";
		status = "okay";
		interrupts = <0x00 0x34 0x01>;
		reg = <0xff638000 0x100 0xff638c00 0x100>;
		interrupt-names = "ddr_bandwidth";
	};

	arm_pmu {
		compatible = "arm,cortex-a15-pmu";
		max-wait-cnt = <0x2710>;
		cpumasks = <0x0f>;
		interrupts = <0x00 0x89 0x04>;
		reg = <0xff634680 0x04>;
		relax-timer-ns = <0x989680>;
	};

	soc {
		compatible = "simple-bus";
		ranges;
		#address-cells = <0x01>;
		#size-cells = <0x01>;

		aobus@ff800000 {
			compatible = "simple-bus";
			ranges = <0x00 0xff800000 0xb000>;
			#address-cells = <0x01>;
			#size-cells = <0x01>;
			phandle = <0xd4>;
			reg = <0xff800000 0xb000>;

			pwm@2000 {
				compatible = "amlogic,g12a-ao-pwm";
				clocks = <0x15 0x15 0x15 0x15>;
				clock-names = "clkin0", "clkin1", "clkin2", "clkin3";
				status = "okay";
				phandle = <0x4a>;
				reg = <0x2000 0x20>;
				#pwm-cells = <0x03>;
			};

			i2c@5000 {
				compatible = "amlogic,meson-g12a-i2c";
				clocks = <0x02 0x2a>;
				clock-names = "clk_i2c";
				status = "disabled";
				#address-cells = <0x01>;
				interrupts = <0x00 0xc3 0x01 0x00 0xc9 0x01>;
				#size-cells = <0x00>;
				phandle = <0xd7>;
				reg = <0x5000 0x20>;
			};

			clock-controller@0 {
				compatible = "amlogic,sm1-aoclkc";
				#reset-cells = <0x01>;
				#clock-cells = <0x01>;
				phandle = <0xd5>;
				reg = <0x00 0x3dc>;
			};

			pwm@7000 {
				compatible = "amlogic,g12a-ao-pwm";
				clocks = <0x15 0x15 0x15 0x15>;
				clock-names = "clkin0", "clkin1", "clkin2", "clkin3";
				status = "disabled";
				phandle = <0xd6>;
				reg = <0x7000 0x20>;
				#pwm-cells = <0x03>;
			};

			cpu_version {
				reg = <0x220 0x04>;
			};

			serial@4000 {
				compatible = "amlogic, meson-uart";
				clocks = <0x15>;
				fifosize = <0x40>;
				clock-names = "clk_uart";
				status = "disabled";
				interrupts = <0x00 0xc5 0x01>;
				phandle = <0xda>;
				reg = <0x4000 0x18>;
				pinctrl-0 = <0x1a>;
				pinctrl-names = "default";
			};

			i2c_slave@6000 {
				compatible = "amlogic, meson-i2c-slave";
				status = "disabled";
				interrupts = <0x00 0xc2 0x01>;
				phandle = <0xd8>;
				reg = <0x6000 0x20>;
				pinctrl-0 = <0x19>;
				pinctrl-names = "default";
			};

			serial@3000 {
				compatible = "amlogic, meson-uart";
				clocks = <0x15>;
				xtal_tick_en = <0x02>;
				fifosize = <0x40>;
				clock-names = "clk_uart";
				status = "okay";
				interrupts = <0x00 0xc1 0x01>;
				phandle = <0xd9>;
				reg = <0x3000 0x18>;
				support-sysrq = <0x00>;
				pinctrl-names = "default";
			};
		};

		periphs@ff634400 {
			compatible = "simple-bus";
			ranges = <0x00 0xff634400 0x400>;
			#address-cells = <0x01>;
			#size-cells = <0x01>;
			phandle = <0xdb>;
			reg = <0xff634400 0x400>;
		};

		audiobus@0xFF660000 {
			compatible = "amlogic, audio-controller", "simple-bus";
			ranges = <0x00 0xff660000 0x3000>;
			#address-cells = <0x01>;
			#size-cells = <0x01>;
			phandle = <0xde>;
			reg = <0xff660000 0x3000>;

			tdm@0 {
				dai-tdm-clk-sel = <0x00>;
				compatible = "amlogic, sm1-snd-tdma";
				clocks = <0x1c 0x24 0x02 0x0c>;
				#sound-dai-cells = <0x00>;
				clock-names = "mclk", "clk_srcpll";
				dai-tdm-oe-lane-slot-mask-out = <0x01 0x00>;
				dai-tdm-lane-slot-mask-in = <0x00 0x01>;
				status = "okay";
				phandle = <0x82>;
				pinctrl-0 = <0x1d 0x1e>;
				pinctrl-names = "tdm_pins";
			};

			pdm {
				compatible = "amlogic, sm1-snd-pdm";
				clocks = <0x1c 0x01 0x02 0x03 0x02 0x0f 0x1c 0x2f 0x1c 0x30>;
				#sound-dai-cells = <0x00>;
				clock-names = "gate", "sysclk_srcpll", "dclk_srcpll", "pdm_dclk", "pdm_sysclk";
				status = "okay";
				phandle = <0x87>;
				filter_mode = <0x01>;
				pinctrl-0 = <0x27>;
				pinctrl-names = "pdm_pins";
			};

			spdif@1 {
				compatible = "amlogic, sm1-snd-spdif-b";
				clocks = <0x02 0x0c 0x1c 0x15 0x1c 0x31>;
				#sound-dai-cells = <0x00>;
				clock-names = "sysclk", "gate_spdifout", "clk_spdifout";
				status = "okay";
				phandle = <0x89>;
			};

			ddr_manager {
				compatible = "amlogic, sm1-audio-ddr-manager";
				interrupts = <0x00 0x94 0x01 0x00 0x95 0x01 0x00 0x96 0x01 0x00 0x31 0x01 0x00 0x98 0x01 0x00 0x99 0x01 0x00 0x9a 0x01 0x00 0x32 0x01>;
				interrupt-names = "toddr_a", "toddr_b", "toddr_c", "toddr_d", "frddr_a", "frddr_b", "frddr_c", "frddr_d";
			};

			vad {
				compatible = "amlogic, snd-vad";
				clocks = <0x1c 0x1b 0x02 0x05 0x1c 0x35>;
				#sound-dai-cells = <0x00>;
				clock-names = "gate", "pll", "clk";
				status = "okay";
				interrupts = <0x00 0x9b 0x01 0x00 0x30 0x01>;
				phandle = <0xe2>;
				src = <0x04>;
				interrupt-names = "irq_wakeup", "irq_frame_sync";
				level = <0x01>;
			};

			i2s2hdmi {
				dai-tdm-clk-sel = <0x02>;
				compatible = "amlogic, g12a-snd-tdmc";
				clocks = <0x1c 0x26 0x02 0x0e>;
				#sound-dai-cells = <0x00>;
				dai-tdm-lane-slot-mask-out = <0x01 0x01 0x01 0x01>;
				clock-names = "mclk", "clk_srcpll";
				i2s2hdmi = <0x01>;
				status = "okay";
				phandle = <0x86>;
			};

			effect {
				eqdrc_module = <0x01>;
				compatible = "amlogic, snd-effect-v3";
				clocks = <0x1c 0x16 0x02 0x05 0x1c 0x34>;
				#sound-dai-cells = <0x00>;
				clock-names = "gate", "srcpll", "eqdrc";
				lane_mask = <0x01>;
				status = "okay";
				phandle = <0xe4>;
				channel_mask = <0x03>;
			};

			loopback@1 {
				datalb-lane-mask-in = <0x01 0x00 0x00 0x00>;
				compatible = "amlogic, sm1-loopbackb";
				clocks = <0x1c 0x01 0x02 0x03 0x02 0x0f 0x1c 0x2f 0x1c 0x30 0x02 0x0c 0x1c 0x24>;
				datain_chmask = <0x0f>;
				#sound-dai-cells = <0x00>;
				clock-names = "pdm_gate", "pdm_sysclk_srcpll", "pdm_dclk_srcpll", "pdm_dclk", "pdm_sysclk", "tdminlb_mpll", "tdminlb_mclk";
				datain_src = <0x04>;
				datain_chnum = <0x04>;
				status = "disabled";
				phandle = <0xe3>;
				mclk-fs = <0x100>;
				datalb_chnum = <0x02>;
				datain-lane-mask-in = <0x01 0x00 0x01 0x00>;
				datalb_src = <0x01>;
				datalb_chmask = <0x03>;
			};

			resample@0 {
				compatible = "amlogic, sm1-resample";
				clocks = <0x02 0x0f 0x1c 0x29 0x1c 0x2c>;
				clock-names = "resample_pll", "resample_src", "resample_clk";
				status = "okay";
				phandle = <0xe1>;
				resample_module = <0x04>;
			};

			tdm@3 {
				dai-tdm-clk-sel = <0x01>;
				compatible = "amlogic, sm1-snd-tdmlb";
				clocks = <0x1c 0x25 0x02 0x0d>;
				#sound-dai-cells = <0x00>;
				clock-names = "mclk", "clk_srcpll";
				lb-src-sel = <0x01>;
				status = "disabled";
				phandle = <0xe0>;
				dai-tdm-lane-lb-slot-mask-in = <0x01 0x00 0x00 0x00>;
			};

			tdm@1 {
				dai-tdm-clk-sel = <0x01>;
				compatible = "amlogic, sm1-snd-tdmb";
				clocks = <0x1c 0x25 0x02 0x0d 0x02 0x0c 0x1c 0x2b>;
				#sound-dai-cells = <0x00>;
				dai-tdm-lane-slot-mask-out = <0x01 0x00 0x00 0x00>;
				clock-names = "mclk", "clk_srcpll", "samesource_srcpll", "samesource_clk";
				samesource_sel = <0x03>;
				dai-tdm-lane-slot-mask-in = <0x00 0x01 0x00 0x00>;
				status = "okay";
				phandle = <0x84>;
				pinctrl-0 = <0x1f 0x20 0x21>;
				pinctrl-names = "tdm_pins";
			};

			audio_clocks {
				compatible = "amlogic, sm1-audio-clocks";
				#clock-cells = <0x01>;
				phandle = <0x1c>;
				reg = <0x00 0xb0>;
			};

			spdif@0 {
				compatible = "amlogic, sm1-snd-spdif-a";
				clocks = <0x02 0x0c 0x02 0x04 0x1c 0x10 0x1c 0x11 0x1c 0x2a 0x1c 0x2b>;
				#sound-dai-cells = <0x00>;
				pinctrl-1 = <0x26>;
				clock-names = "sysclk", "fixed_clk", "gate_spdifin", "gate_spdifout", "clk_spdifin", "clk_spdifout";
				status = "okay";
				interrupts = <0x00 0x97 0x01>;
				phandle = <0x88>;
				clk_tuning_enable = <0x01>;
				pinctrl-0 = <0x25>;
				interrupt-names = "irq_spdifin";
				pinctrl-names = "spdif_pins", "spdif_pins_mute";
			};

			loopback@0 {
				datalb-lane-mask-in = <0x01 0x00 0x00 0x00>;
				compatible = "amlogic, sm1-loopbacka";
				clocks = <0x1c 0x01 0x02 0x03 0x02 0x0f 0x1c 0x2f 0x1c 0x30 0x02 0x0c 0x1c 0x24>;
				datain_chmask = <0x03>;
				#sound-dai-cells = <0x00>;
				clock-names = "pdm_gate", "pdm_sysclk_srcpll", "pdm_dclk_srcpll", "pdm_dclk", "pdm_sysclk", "tdminlb_mpll", "tdminlb_mclk";
				datain_src = <0x04>;
				datain_chnum = <0x02>;
				status = "okay";
				phandle = <0x8b>;
				mclk-fs = <0x100>;
				datalb_chnum = <0x02>;
				datain-lane-mask-in = <0x01 0x00 0x00 0x00>;
				datalb_src = <0x01>;
				datalb_chmask = <0x03>;
			};

			tdm@2 {
				dai-tdm-clk-sel = <0x02>;
				compatible = "amlogic, sm1-snd-tdmc";
				clocks = <0x1c 0x26 0x02 0x0e>;
				#dai-tdm-lane-oe-slot-mask-in = <0x00 0x00 0x00 0x00>;
				#sound-dai-cells = <0x00>;
				clock-names = "mclk", "clk_srcpll";
				#dai-tdm-lane-slot-mask-out = <0x01 0x00 0x01 0x01>;
				dai-tdm-lane-slot-mask-in = <0x01 0x00 0x00 0x00>;
				status = "okay";
				phandle = <0xdf>;
				#dai-tdm-lane-oe-slot-mask-out = <0x01 0x00 0x00 0x00>;
				pinctrl-0 = <0x22 0x23 0x24>;
				pinctrl-names = "tdm_pins";
			};
		};

		ion_dev {
			compatible = "amlogic, ion_dev";
			memory-region = <0x1b>;
		};

		aml_snd_iomap {
			compatible = "amlogic, snd-iomap";
			ranges;
			status = "okay";
			#address-cells = <0x01>;
			#size-cells = <0x01>;

			resampleB_base {
				reg = <0xff664000 0x104>;
			};

			reset_base {
				reg = <0xffd01000 0x1000>;
			};

			pdm_bus {
				reg = <0xff661000 0x400>;
			};

			resampleA_base {
				reg = <0xff661c00 0x104>;
			};

			vad_base {
				reg = <0xff661800 0x400>;
			};

			eqdrc_base {
				reg = <0xff662000 0x1000>;
			};

			audiolocker_base {
				reg = <0xff661400 0x400>;
			};

			audiobus_base {
				reg = <0xff660000 0x1000>;
			};
		};

		bus@ff663000 {
			compatible = "simple-bus";
			ranges = <0x00 0xff663000 0x1000>;
			#address-cells = <0x01>;
			#size-cells = <0x01>;
			phandle = <0xe5>;
			reg = <0xff663000 0x1000>;

			earc@0 {
				compatible = "amlogic, sm1-snd-earc";
				clocks = <0x1c 0x38 0x1c 0x39 0x02 0x04 0x02 0x04 0x1c 0x36 0x1c 0x37 0x02 0x04 0x02 0x0d>;
				#sound-dai-cells = <0x00>;
				reg-names = "rx_cmdc", "rx_dmac", "rx_top";
				clock-names = "rx_cmdc", "rx_dmac", "rx_cmdc_srcpll", "rx_dmac_srcpll";
				status = "okay";
				interrupts = <0x00 0x57 0x04>;
				phandle = <0x8a>;
				reg = <0x800 0x400 0xc00 0x200 0xe00 0x200>;
				interrupt-names = "earc_rx";
			};
		};

		cbus@ffd00000 {
			compatible = "simple-bus";
			ranges = <0x00 0xffd00000 0x26000>;
			#address-cells = <0x01>;
			#size-cells = <0x01>;
			phandle = <0xc9>;
			reg = <0xffd00000 0x26000>;

			pwm@1b000 {
				compatible = "amlogic,g12a-ee-pwm";
				clocks = <0x15 0x15 0x15 0x15>;
				clock-names = "clkin0", "clkin1", "clkin2", "clkin3";
				status = "disabled";
				phandle = <0xcb>;
				reg = <0x1b000 0x20>;
				#pwm-cells = <0x03>;
			};

			i2c@1d000 {
				compatible = "amlogic,meson-g12a-i2c";
				clocks = <0x02 0x2a>;
				clock-names = "clk_i2c";
				status = "disabled";
				#address-cells = <0x01>;
				interrupts = <0x00 0xd7 0x01 0x00 0x5e 0x01>;
				#size-cells = <0x00>;
				phandle = <0xcf>;
				reg = <0x1d000 0x20>;
			};

			pwm@1a000 {
				compatible = "amlogic,g12a-ee-pwm";
				clocks = <0x15 0x15 0x15 0x15>;
				clock-names = "clkin0", "clkin1", "clkin2", "clkin3";
				status = "disabled";
				phandle = <0xcc>;
				reg = <0x1a000 0x20>;
				#pwm-cells = <0x03>;
			};

			spi@13000 {
				compatible = "amlogic,meson-g12a-spicc";
				clocks = <0x02 0x29 0x02 0xd1>;
				clock-names = "core", "comp";
				status = "disabled";
				#address-cells = <0x01>;
				interrupts = <0x00 0x51 0x04>;
				#size-cells = <0x00>;
				phandle = <0xd2>;
				reg = <0x13000 0x44>;
			};

			i2c@1f000 {
				compatible = "amlogic,meson-g12a-i2c";
				clocks = <0x02 0x2a>;
				clock-names = "clk_i2c";
				status = "disabled";
				#address-cells = <0x01>;
				interrupts = <0x00 0x15 0x01 0x00 0x5b 0x01>;
				#size-cells = <0x00>;
				phandle = <0xcd>;
				reg = <0x1f000 0x20>;
			};

			i2c@1c000 {
				compatible = "amlogic,meson-g12a-i2c";
				clocks = <0x02 0x2a>;
				clock-names = "clk_i2c";
				status = "okay";
				#address-cells = <0x01>;
				interrupts = <0x00 0x27 0x01 0x00 0x5f 0x01>;
				#size-cells = <0x00>;
				phandle = <0xd0>;
				reg = <0x1c000 0x20>;
				clock-frequency = <0x186a0>;
				pinctrl-0 = <0x18>;
				pinctrl-names = "default";

				hym8563@51 {
					compatible = "haoyu,hym8563";
					#clock-cells = <0x00>;
					phandle = <0xd1>;
					reg = <0x51>;
					clock-output-names = "xin32k";
					clock-frequency = <0x8000>;
				};
			};

			meson_clk_msr {
				compatible = "amlogic, sm1-measure";
				ringctrl = <0xff6345fc>;
				reg = <0x18004 0x04 0x1800c 0x04>;
			};

			interrupt-controller@f080 {
				compatible = "amlogic,meson-gpio-intc", "amlogic,meson-sm1-gpio-intc";
				status = "okay";
				#interrupt-cells = <0x02>;
				phandle = <0xca>;
				reg = <0xf080 0x10>;
				amlogic,channel-interrupts = <0x40 0x41 0x42 0x43 0x44 0x45 0x46 0x47>;
				interrupt-controller;
			};

			spi@15000 {
				compatible = "amlogic,meson-g12a-spicc";
				clocks = <0x02 0x2f 0x02 0xd5>;
				clock-names = "core", "comp";
				status = "disabled";
				#address-cells = <0x01>;
				interrupts = <0x00 0x5a 0x04>;
				#size-cells = <0x00>;
				phandle = <0xd3>;
				reg = <0x15000 0x44>;
			};

			i2c@1e000 {
				compatible = "amlogic,meson-g12a-i2c";
				clocks = <0x02 0x2a>;
				clock-names = "clk_i2c";
				status = "disabled";
				#address-cells = <0x01>;
				interrupts = <0x00 0xd6 0x01 0x00 0x5c 0x01>;
				#size-cells = <0x00>;
				phandle = <0xce>;
				reg = <0x1e000 0x20>;
			};

			pwm@19000 {
				compatible = "amlogic,g12a-ee-pwm";
				clocks = <0x15 0x15 0x15 0x15>;
				clock-names = "clkin0", "clkin1", "clkin2", "clkin3";
				status = "okay";
				phandle = <0x67>;
				reg = <0x19000 0x20>;
				#pwm-cells = <0x03>;
			};
		};

		hiubus@ff63c000 {
			compatible = "simple-bus";
			ranges = <0x00 0xff63c000 0x2000>;
			#address-cells = <0x01>;
			#size-cells = <0x01>;
			phandle = <0xdc>;
			reg = <0xff63c000 0x2000>;

			clock-controller@0 {
				compatible = "amlogic,sm1-clkc-1";
				#clock-cells = <0x01>;
				phandle = <0x02>;
				reg = <0x00 0x3dc>;
			};

			clock-controller@1 {
				compatible = "amlogic,sm1-clkc-2";
				clocks = <0x02 0x02>;
				clock-names = "clkin0";
				own-dsu-clk;
				#clock-cells = <0x01>;
				phandle = <0xdd>;
				reg = <0x00 0x3dc>;
			};
		};
	};

	vdec {
		compatible = "amlogic, vdec";
		dev_name = "vdec.0";
		status = "okay";
		interrupts = <0x00 0x03 0x01 0x00 0x17 0x01 0x00 0x20 0x01 0x00 0x2b 0x01 0x00 0x2c 0x01 0x00 0x2d 0x01 0x00 0x48 0x01>;
		interrupt-names = "vsync", "demux", "parser", "mailbox_0", "mailbox_1", "mailbox_2", "parser_b";
	};

	efusekey {
		key3 = <0x81>;
		keynum = <0x04>;
		key1 = <0x7f>;
		key2 = <0x80>;
		phandle = <0x4b>;
		key0 = <0x7e>;

		key_2 {
			offset = <0x0c>;
			keyname = "mac_wifi";
			size = <0x06>;
			phandle = <0x80>;
		};

		key_0 {
			offset = <0x00>;
			keyname = "mac";
			size = <0x06>;
			phandle = <0x7e>;
		};

		key_3 {
			offset = <0x12>;
			keyname = "usid";
			size = <0x10>;
			phandle = <0x81>;
		};

		key_1 {
			offset = <0x06>;
			keyname = "mac_bt";
			size = <0x06>;
			phandle = <0x7f>;
		};
	};

	bifrost {
		compatible = "arm,malit60x", "arm,malit6xx", "arm,mali-midgard";
		clocks = <0x02 0x83 0x02 0x07>;
		sc_mpp = <0x01>;
		clock-names = "gpu_mux", "gp0_pll";
		tbl = <0x03 0x04 0x05 0x06 0x07 0x07>;
		interrupt-parent = <0x01>;
		interrupts = <0x00 0xa0 0x04 0x00 0xa1 0x04 0x00 0xa2 0x04>;
		phandle = <0x8d>;
		reg = <0xffe40000 0x4000 0xffd01000 0x1000 0xff800000 0x1000 0xff63c000 0x1000 0xffd01000 0x1000>;
		#cooling-cells = <0x02>;
		interrupt-names = "GPU", "MMU", "JOB";
		num_of_pp = <0x02>;

		dvfs500_cfg {
			clk_reg = <0xa00>;
			voltage = <0x47e>;
			threshold = <0xb4 0xdc>;
			clk_parent = "fclk_div4";
			clkp_freq = <0x1dcd6500>;
			keep_count = <0x05>;
			clk_freq = <0x1dcd6500>;
			phandle = <0x05>;
		};

		dvfs666_cfg {
			clk_reg = <0x800>;
			voltage = <0x47e>;
			threshold = <0xd2 0xec>;
			clk_parent = "fclk_div3";
			clkp_freq = <0x27bc86aa>;
			keep_count = <0x05>;
			clk_freq = <0x27bc86aa>;
			phandle = <0x06>;
		};

		dvfs285_cfg {
			clk_reg = <0xe00>;
			voltage = <0x47e>;
			threshold = <0x64 0xbe>;
			clk_parent = "fclk_div7";
			clkp_freq = <0x1107a76d>;
			keep_count = <0x05>;
			clk_freq = <0x1107a76d>;
			phandle = <0x03>;
		};

		dvfs800_cfg {
			clk_reg = <0x600>;
			voltage = <0x47e>;
			threshold = <0xe6 0xff>;
			clk_parent = "fclk_div2p5";
			clkp_freq = <0x2faf0800>;
			keep_count = <0x05>;
			clk_freq = <0x2faf0800>;
			phandle = <0x90>;
		};

		clk125_cfg {
			clk_reg = <0xa03>;
			voltage = <0x47e>;
			threshold = <0x1e 0x78>;
			clk_parent = "fclk_div4";
			clkp_freq = <0x1dcd6500>;
			keep_count = <0x05>;
			clk_freq = <0x7735940>;
			phandle = <0x8e>;
		};

		dvfs250_cfg {
			clk_reg = <0xa01>;
			voltage = <0x47e>;
			threshold = <0x50 0xaa>;
			clk_parent = "fclk_div4";
			clkp_freq = <0x1dcd6500>;
			keep_count = <0x05>;
			clk_freq = <0xee6b280>;
			phandle = <0x8f>;
		};

		dvfs850_cfg {
			clk_reg = <0x200>;
			voltage = <0x47e>;
			threshold = <0xe6 0xff>;
			clk_parent = "gp0_pll";
			clkp_freq = <0x326cef80>;
			keep_count = <0x05>;
			clk_freq = <0x326cef80>;
			phandle = <0x07>;
		};

		dvfs400_cfg {
			clk_reg = <0xc00>;
			voltage = <0x47e>;
			threshold = <0x98 0xcf>;
			clk_parent = "fclk_div5";
			clkp_freq = <0x17d78400>;
			keep_count = <0x05>;
			clk_freq = <0x17d78400>;
			phandle = <0x04>;
		};
	};

	ionvideo {
		compatible = "amlogic, ionvideo";
		dev_name = "ionvideo";
		status = "okay";
	};

	vpu {
		compatible = "amlogic, vpu-sm1";
		clocks = <0x02 0x95 0x02 0x4c 0x02 0x87 0x02 0x8b 0x02 0x8c>;
		dev_name = "vpu";
		clock-names = "vapb_clk", "vpu_intr_gate", "vpu_clk0", "vpu_clk1", "vpu_clk";
		status = "okay";
		clk_level = <0x07>;
		phandle = <0x93>;
	};

	aml_reboot {
		compatible = "aml, reboot";
		sys_reset = <0x84000009>;
		sys_poweroff = <0x84000008>;
	};

	eqdrc {
		eqdrc_module = <0x01>;
		lane_mask = <0x01>;
		phandle = <0x108>;
		channel_mask = <0x03>;
	};

	psci {
		compatible = "arm,psci-0.2";
		method = "smc";
	};

	unifykey {
		unifykey-index-10 = <0x77>;
		compatible = "amlogic, unifykey";
		unifykey-index-7 = <0x74>;
		unifykey-index-5 = <0x72>;
		unifykey-index-15 = <0x7c>;
		unifykey-index-3 = <0x70>;
		unifykey-num = <0x11>;
		unifykey-index-13 = <0x7a>;
		unifykey-index-1 = <0x6e>;
		unifykey-index-11 = <0x78>;
		status = "ok";
		unifykey-index-8 = <0x75>;
		unifykey-index-6 = <0x73>;
		unifykey-index-16 = <0x7d>;
		unifykey-index-4 = <0x71>;
		unifykey-index-14 = <0x7b>;
		unifykey-index-2 = <0x6f>;
		unifykey-index-12 = <0x79>;
		unifykey-index-0 = <0x6d>;
		unifykey-index-9 = <0x76>;

		key_14 {
			key-device = "secure";
			key-name = "attestationkeybox";
			key-permit = "read", "write", "del";
			phandle = <0x7b>;
		};

		key_2 {
			key-device = "secure";
			key-type = "sha1";
			key-name = "hdcp";
			key-permit = "read", "write", "del";
			phandle = <0x6f>;
		};

		key_12 {
			key-device = "secure";
			key-name = "prpubkeybox";
			key-permit = "read", "write", "del";
			phandle = <0x79>;
		};

		key_0 {
			key-device = "normal";
			key-name = "usid";
			key-permit = "read", "write", "del";
			phandle = <0x6d>;
		};

		key_9 {
			key-device = "normal";
			key-name = "deviceid";
			key-permit = "read", "write", "del";
			phandle = <0x76>;
		};

		key_10 {
			key-device = "secure";
			key-name = "hdcp22_fw_private";
			key-permit = "read", "write", "del";
			phandle = <0x77>;
		};

		key_7 {
			key-device = "normal";
			key-name = "hdcp2_rx";
			key-permit = "read", "write", "del";
			phandle = <0x74>;
		};

		key_5 {
			key-device = "normal";
			key-type = "mac";
			key-name = "mac_wifi";
			key-permit = "read", "write", "del";
			phandle = <0x72>;
		};

		key_15 {
			key-device = "secure";
			key-name = "netflix_mgkid";
			key-permit = "read", "write", "del";
			phandle = <0x7c>;
		};

		key_3 {
			key-device = "efuse";
			key-name = "secure_boot_set";
			key-permit = "write";
			phandle = <0x70>;
		};

		key_13 {
			key-device = "secure";
			key-name = "prprivkeybox";
			key-permit = "read", "write", "del";
			phandle = <0x7a>;
		};

		key_1 {
			key-device = "normal";
			key-name = "mac";
			key-permit = "read", "write", "del";
			phandle = <0x6e>;
		};

		key_11 {
			key-device = "secure";
			key-name = "PlayReadykeybox25";
			key-permit = "read", "write", "del";
			phandle = <0x78>;
		};

		key_8 {
			key-device = "secure";
			key-name = "widevinekeybox";
			key-permit = "read", "write", "del";
			phandle = <0x75>;
		};

		key_6 {
			key-device = "normal";
			key-name = "hdcp2_tx";
			key-permit = "read", "write", "del";
			phandle = <0x73>;
		};

		key_16 {
			key-device = "secure";
			key-name = "attestationdevidbox";
			key-permit = "read", "write", "del";
			phandle = <0x7d>;
		};

		key_4 {
			key-device = "normal";
			key-type = "mac";
			key-name = "mac_bt";
			key-permit = "read", "write", "del";
			phandle = <0x71>;
		};
	};

	vdin0 {
		compatible = "amlogic, vdin";
		tv_bit_mode = <0x15>;
		dev_name = "vdin0";
		flag_cma = <0x00>;
		status = "disabled";
		interrupts = <0x00 0x53 0x01>;
		phandle = <0xed>;
		rdma-irq = <0x02>;
		vdin_id = <0x00>;
		reserve-iomap = "true";
	};

	led {
		compatible = "sysled-rgb-leds";
		default-active-trigger = "input-invert";
		default-active-color = <0xff00ff>;
		r-gpios = <0x64 0x0a 0x00>;
		default-hibernate-color = <0xff0000>;
		default-suspend-color = <0xff>;
		default-hibernate-mode = "on";
		status = "okay";
		b-gpios = <0x64 0x0b 0x00>;
		default-suspend-trigger = "default-on";
	};

	firmware {

		android {
			compatible = "android,firmware";

			fstab {
				compatible = "android,fstab";

				vendor {
					compatible = "android,vendor";
					dev = "/dev/block/vendor";
					type = "ext4";
					fsmgr_flags = "wait";
					mnt_flags = "ro,barrier=1,inode_readahead_blks=8";
				};

				product {
					compatible = "android,product";
					dev = "/dev/block/product";
					type = "ext4";
					fsmgr_flags = "wait";
					mnt_flags = "ro,barrier=1,inode_readahead_blks=8";
				};

				odm {
					compatible = "android,odm";
					dev = "/dev/block/odm";
					type = "ext4";
					fsmgr_flags = "wait";
					mnt_flags = "ro,barrier=1,inode_readahead_blks=8";
				};
			};

			vbmeta {
				compatible = "android,vbmeta";
				parts = "vbmeta,boot,system,vendor";
				by_name_prefix = "/dev/block";
			};
		};
	};

	pcieA@fc000000 {
		pcie-ctrl-a-rst-bit = <0x0c>;
		reset-gpio = <0x14 0x49 0x00>;
		compatible = "amlogic, amlogic-pcie-v2", "snps,dw-pcie";
		clocks = <0x02 0x18 0x02 0x3f 0x02 0x42>;
		gpio-type = <0x02>;
		reg-names = "elbi", "cfg", "config", "phy", "reset";
		device_type = "pci";
		num-lanes = <0x01>;
		clock-names = "pcie_refpll", "pcie", "pcie_phy";
		pcie-hhi-mem-pd-shift = <0x1a>;
		interrupt-map-mask = <0x00 0x00 0x00 0x00>;
		ranges = <0x81000000 0x00 0x00 0xfc600000 0x00 0x100000 0x82000000 0xfc700000 0x00 0xfc700000 0x00 0x1900000>;
		pcie-apb-rst-bit = <0x0f>;
		status = "disable";
		#interrupt-cells = <0x01>;
		bus-range = <0x00 0xff>;
		#address-cells = <0x03>;
		interrupts = <0x00 0xdd 0x00>;
		pcie-ctrl-iso-shift = <0x12>;
		interrupt-map = <0x00 0x00 0x00 0x00 0x01 0x00 0xdf 0x01>;
		pcie-num = <0x01>;
		pcie-ctrl-sleep-shift = <0x12>;
		#size-cells = <0x02>;
		pcie-hhi-mem-pd-mask = <0x0f>;
		phandle = <0xea>;
		pcie-phy-rst-bit = <0x0e>;
		reg = <0xfc000000 0x400000 0xff648000 0x2000 0xfc400000 0x200000 0xff646000 0x2000 0xffd01080 0x10>;
		pwr-ctl = <0x01>;
	};

	rc@0xff808040 {
		map = <0x29>;
		compatible = "amlogic, aml_remote";
		dev_name = "meson-remote";
		led_blink = <0x01>;
		max_frame_time = <0xc8>;
		led_blink_frq = <0x64>;
		status = "okay";
		interrupts = <0x00 0xc4 0x01>;
		phandle = <0xe6>;
		reg = <0xff808040 0x44 0xff808000 0x20>;
		pinctrl-0 = <0x28>;
		protocol = <0x01>;
		pinctrl-names = "default";
	};

	pinctrl@ff800014 {
		compatible = "amlogic,meson-g12a-aobus-pinctrl";
		ranges;
		#address-cells = <0x01>;
		#size-cells = <0x01>;
		phandle = <0x95>;

		pwm_ao_b {
			phandle = <0x9b>;

			mux {
				groups = "pwm_ao_b";
				function = "pwm_ao_b";
			};
		};

		remote_pin {
			phandle = <0x28>;

			mux {
				groups = "remote_input_ao";
				function = "remote_input_ao";
			};
		};

		ao_i2c_pins1 {
			phandle = <0x97>;

			mux {
				drive-strength = <0x02>;
				groups = "i2c_ao_sck", "i2c_ao_sda";
				function = "i2c_ao";
			};
		};

		ao_cecb {
			phandle = <0xa2>;

			mux {
				groups = "cec_ao_b";
				function = "cec_ao";
			};
		};

		sd_to_ao_uart_clr_pins {
			phandle = <0x3f>;

			mux {
				groups = "GPIOAO_0", "GPIOAO_1";
				function = "gpio_aobus";
			};
		};

		pwm_ao_d_pins2 {
			phandle = <0xa0>;

			mux {
				groups = "pwm_ao_d_10";
				function = "pwm_ao_d";
			};
		};

		pwm_ao_c_pins1 {
			phandle = <0x9c>;

			mux {
				groups = "pwm_ao_c_4";
				function = "pwm_ao_c";
			};
		};

		jtag_apao_pin {
			phandle = <0x16>;

			mux {
				groups = "jtag_a_tdi", "jtag_a_tdo", "jtag_a_clk", "jtag_a_tms";
				function = "jtag_a";
			};
		};

		pwm_ao_c_hiz {
			phandle = <0x9e>;

			mux {
				groups = "pwm_ao_c_hiz_4";
				function = "pwm_ao_c";
			};
		};

		ao_i2c_pins2 {
			phandle = <0x98>;

			mux {
				drive-strength = <0x02>;
				groups = "i2c_ao_sck_e", "i2c_ao_sda_e";
				function = "i2c_ao";
			};
		};

		ao_i2c_slave_pins {
			phandle = <0x19>;

			mux {
				groups = "i2c_ao_slave_sck", "i2c_ao_slave_sda";
				function = "i2c_ao_slave";
			};
		};

		ao_uart {
			phandle = <0x96>;

			mux {
				groups = "uart_ao_tx_a", "uart_ao_rx_a";
				function = "uart_ao_a";
			};
		};

		pwm_ao_a {
			phandle = <0x99>;

			mux {
				groups = "pwm_ao_a";
				function = "pwm_ao_a";
			};
		};

		ao-bank@ff800014 {
			reg-names = "mux", "gpio", "drive-strength";
			gpio-controller;
			phandle = <0x64>;
			reg = <0xff800014 0x08 0xff800024 0x14 0xff80001c 0x08>;
			#gpio-cells = <0x02>;
		};

		pwm_ao_d_pins3 {
			phandle = <0x8c>;

			mux {
				groups = "pwm_ao_d_e";
				function = "pwm_ao_d";
			};
		};

		ao_b_uart {
			phandle = <0x1a>;

			mux {
				groups = "uart_ao_tx_b_2", "uart_ao_rx_b_3";
				function = "uart_ao_b";
			};
		};

		sd_to_ao_uart_pins {
			phandle = <0x41>;

			mux {
				groups = "uart_ao_tx_a", "uart_ao_rx_a";
				function = "uart_ao_a";
				input-enable;
				bias-pull-up;
			};
		};

		ao_ceca {
			phandle = <0xa1>;

			mux {
				groups = "cec_ao_a";
				function = "cec_ao";
			};
		};

		pwm_ao_d_pins1 {
			phandle = <0x9f>;

			mux {
				groups = "pwm_ao_d_5";
				function = "pwm_ao_d";
			};
		};

		irblaster_pin {
			phandle = <0x38>;

			mux {
				groups = "remote_out_ao";
				function = "remote_out_ao";
			};
		};

		pwm_ao_c_pins2 {
			phandle = <0x9d>;

			mux {
				groups = "pwm_ao_c_6";
				function = "pwm_ao_c";
			};
		};

		pwm_ao_a_hiz {
			phandle = <0x9a>;

			mux {
				groups = "pwm_ao_a_hiz";
				function = "pwm_ao_a";
			};
		};
	};

	partitions {
		part-7 = <0x5a>;
		parts = <0x11>;
		part-5 = <0x58>;
		part-16 = <0x63>;
		part-3 = <0x56>;
		part-14 = <0x61>;
		part-1 = <0x54>;
		part-12 = <0x5f>;
		part-10 = <0x5d>;
		part-8 = <0x5b>;
		part-6 = <0x59>;
		phandle = <0x103>;
		part-4 = <0x57>;
		part-15 = <0x62>;
		part-2 = <0x55>;
		part-13 = <0x60>;
		part-0 = <0x53>;
		part-11 = <0x5e>;
		part-9 = <0x5c>;

		logo {
			pname = "logo";
			mask = <0x01>;
			size = <0x00 0x800000>;
			phandle = <0x53>;
		};

		vendor {
			pname = "vendor";
			mask = <0x01>;
			size = <0x00 0x10000000>;
			phandle = <0x5e>;
		};

		param {
			pname = "param";
			mask = <0x02>;
			size = <0x00 0x1000000>;
			phandle = <0x58>;
		};

		dtbo {
			pname = "dtbo";
			mask = <0x01>;
			size = <0x00 0x800000>;
			phandle = <0x56>;
		};

		misc {
			pname = "misc";
			mask = <0x01>;
			size = <0x00 0x800000>;
			phandle = <0x55>;
		};

		tee {
			pname = "tee";
			mask = <0x01>;
			size = <0x00 0x2000000>;
			phandle = <0x5d>;
		};

		system {
			pname = "system";
			mask = <0x01>;
			size = <0x00 0x50000000>;
			phandle = <0x60>;
		};

		cri_data {
			pname = "cri_data";
			mask = <0x02>;
			size = <0x00 0x800000>;
			phandle = <0x57>;
		};

		product {
			pname = "product";
			mask = <0x01>;
			size = <0x00 0x8000000>;
			phandle = <0x61>;
		};

		metadata {
			pname = "metadata";
			mask = <0x01>;
			size = <0x00 0x1000000>;
			phandle = <0x5b>;
		};

		vbmeta {
			pname = "vbmeta";
			mask = <0x01>;
			size = <0x00 0x200000>;
			phandle = <0x5c>;
		};

		odm {
			pname = "odm";
			mask = <0x01>;
			size = <0x00 0x8000000>;
			phandle = <0x5f>;
		};

		cache {
			pname = "cache";
			mask = <0x02>;
			size = <0x00 0x46000000>;
			phandle = <0x62>;
		};

		data {
			pname = "data";
			mask = <0x04>;
			size = <0xffffffff 0xffffffff>;
			phandle = <0x63>;
		};

		recovery {
			pname = "recovery";
			mask = <0x01>;
			size = <0x00 0x1800000>;
			phandle = <0x54>;
		};

		boot {
			pname = "boot";
			mask = <0x01>;
			size = <0x00 0x1000000>;
			phandle = <0x59>;
		};

		rsv {
			pname = "rsv";
			mask = <0x01>;
			size = <0x00 0x1000000>;
			phandle = <0x5a>;
		};
	};

	xtal-clk {
		compatible = "fixed-clock";
		#clock-cells = <0x00>;
		phandle = <0x15>;
		clock-output-names = "xtal";
		clock-frequency = <0x16e3600>;
	};

	vdac {
		compatible = "amlogic, vdac-sm1";
		status = "okay";
	};

	pwmao_d-regulator {
		compatible = "pwm-regulator";
		status = "okay";
		voltage-table = <0xf9060 0x00 0xf6950 0x03 0xf4240 0x06 0xf1b30 0x0a 0xef420 0x0d 0xecd10 0x10 0xea600 0x14 0xe7ef0 0x17 0xe57e0 0x1a 0xe30d0 0x1e 0xe09c0 0x21 0xde2b0 0x24 0xdbba0 0x28 0xd9490 0x2b 0xd6d80 0x2e 0xd4670 0x32 0xd1f60 0x35 0xcf850 0x38 0xcd140 0x3c 0xcaa30 0x3f 0xc8320 0x43 0xc5c10 0x46 0xc3500 0x49 0xc0df0 0x4c 0xbe6e0 0x50 0xbbfd0 0x53 0xb98c0 0x56 0xb71b0 0x5a 0xb4aa0 0x5d 0xb2390 0x60 0xafc80 0x64>;
		phandle = <0x0e>;
		regulator-min-microvolt = <0xafc80>;
		regulator-max-microvolt = <0xf9060>;
		max-duty-cycle = <0x4e2>;
		regulator-always-on;
		pwms = <0x4a 0x01 0x4e2 0x00>;
		regulator-name = "vddcpu0";
	};

	aliases {
		i2c3 = "/soc/cbus@ffd00000/i2c@1c000";
		i2c1 = "/soc/cbus@ffd00000/i2c@1e000";
		tsensor0 = "/p_tsensor@ff634800";
		serial3 = "/serial@ffd22000";
		serial1 = "/serial@ffd24000";
		i2c4 = "/soc/aobus@ff800000/i2c@5000";
		i2c2 = "/soc/cbus@ffd00000/i2c@1d000";
		i2c0 = "/soc/cbus@ffd00000/i2c@1f000";
		tsensor1 = "/d_tsensor@ff634c00";
		serial4 = "/soc/aobus@ff800000/serial@4000";
		serial2 = "/serial@ffd23000";
		serial0 = "/soc/aobus@ff800000/serial@3000";
	};

	chosen {
		bootargs = "init=/init console=ttyS0,115200 no_console_suspend earlyprintk=aml-uart,0xff803000 ramoops.pstore_en=1 ramoops.record_size=0x8000 ramoops.console_size=0x4000 hdr_policy=1 hdr_priority= otg_device=0 usb3_off=0 reboot_mode_android=normal logo=osd0,loaded,0x3d800000 fb_width=1920 fb_height=1080 display_bpp=16 outputmode=1080p60hz vout=1080p60hz,enable panel_type=lcd_1 lcd_ctrl=0x00000000 hdmitx=0x2f,444,8bit hdmimode=1080p60hz hdmichecksum=0x00000000 frac_rate_policy=0 hdmi_read_edid=1 cvbsmode=576cvbs osd_reverse=0 video_reverse=0 irq_check_en=0 androidboot.selinux=permissive androidboot.firstboot=0 jtag=disable androidboot.hardware=amlogic androidboot.bootloader=U-Boot 2015.01 androidboot.build.expect.baseband=N/A androidboot.serialno=X3P2009000004292 mac=d0:5f:64:d1:22:a4 androidboot.mac=d0:5f:64:d1:22:a4 androidboot.oem.key1=ATV00104319 androidboot.rpmb_state=0 ug_magisk=0 skip_initramfs rootfstype=ext4 uboot=123_2015.01 androidboot.dtbo_idx=0 --cmdline root=/dev/mmcblk0p18 buildvariant=userdebug";
		linux,initrd-start = <0x9fc7000>;
		linux,initrd-end = <0x9fff62f>;
	};

	custom_maps {
		map2 = <0x2c>;
		map0 = <0x2a>;
		phandle = <0x29>;
		mapnum = <0x01>;
		map1 = <0x2b>;

		map_1 {
			release_delay = <0x50>;
			keymap = <0x10002 0x20003 0x30004 0x40005 0x50006 0x60007 0x70008 0x80009 0x9000a 0xa000b 0x1f01d2 0x15008b 0x16000f 0xc0192 0xd0193 0xe0073 0xf0072 0x110066 0x1c006a 0x1b0069 0x190067 0x1a006c 0x1d001c 0x170071 0x4900db 0x43009e 0x1201d5 0x1401d6 0x1801d7 0x590166 0x5a00a6 0x100074 0x4200a5 0x4400a3 0x1e00a8 0x4b00d0 0x5800a4 0x460082 0x400083 0x380046 0x5701d0 0x5b01d1 0x54018e 0x4c018f 0x4e0190 0x550191 0x5300ed 0x5200ee 0x3900d4 0x4100d5 0xb00d6 0xd8 0x1300d9>;
			customcode = <0xfe01>;
			mapname = "amlogic-remote-2";
			size = <0x35>;
			phandle = <0x2b>;
		};

		map_2 {
			release_delay = <0x50>;
			keymap = <0xca0067 0xd2006c 0x990069 0xc1006a 0xce0061 0x450074 0xc50085 0x800071 0xd0000f 0xd6007d 0x950066 0xdd0068 0x8c006d 0x890083 0x9c0082 0x9a0078 0xcd0079>;
			customcode = <0xbd02>;
			mapname = "amlogic-remote-3";
			size = <0x11>;
			phandle = <0x2c>;
		};

		map_0 {
			release_delay = <0x50>;
			keymap = <0x540002 0x480003 0x70004 0x500005 0x120006 0x110007 0x4c0008 0xe0009 0xd000a 0xc000b 0x60066 0x460067 0x40009e 0x470069 0x550061 0x15006a 0x4008b 0x16006c 0x17008c 0x140072 0x100073 0x180074 0x22004b 0x8004c 0x3c004d 0x4f004e 0x560244 0x570077 0x1f000e 0x5b0041 0x190071>;
			customcode = <0xff00>;
			mapname = "X2CUBE-remote";
			size = <0x1f>;
			phandle = <0x2a>;
		};
	};

	rng {
		quality = [03 e8];
		compatible = "amlogic,meson-rng";
		status = "okay";
		#address-cells = <0x01>;
		#size-cells = <0x01>;
		reg = <0xff630218 0x04>;
	};

	dummy-battery {
		compatible = "amlogic, dummy-battery";
		status = "okay";
		phandle = <0x106>;
	};

	fb {
		mem_alloc = <0x00>;
		compatible = "amlogic, meson-sm1";
		clocks = <0x02 0xc9>;
		dev_name = "meson-fb";
		clock-names = "vpu_clkc";
		status = "okay";
		interrupts = <0x00 0x03 0x01 0x00 0x38 0x01 0x00 0x59 0x01>;
		display_size_default = <0x780 0x438 0x780 0x870 0x20>;
		memory-region = <0x37>;
		mem_size = <0x800000 0x1980000 0x100000 0x100000 0x800000>;
		scale_mode = <0x01>;
		phandle = <0xf1>;
		pxp_mode = <0x00>;
		display_mode_default = "1080p60hz";
		interrupt-names = "viu-vsync", "viu2-vsync", "rdma";
		logo_addr = "0x7f800000";
	};

	cvbsout {
		compatible = "amlogic, cvbsout-sm1";
		clocks = <0x02 0x55 0x02 0x4e 0x02 0x4f 0x02 0x57>;
		dev_name = "cvbsout";
		performance = <0x1bf0 0x09 0x1b56 0x333 0x1b12 0x8080 0x1b05 0xfd 0x1c59 0xf850 0xffff 0x00>;
		performance_revB_telecom = <0x1bf0 0x09 0x1b56 0x546 0x1b12 0x8080 0x1b05 0x09 0x1c59 0xf850 0xffff 0x00>;
		clock-names = "venci_top_gate", "venci_0_gate", "venci_1_gate", "vdac_clk_gate";
		status = "okay";
		performance_sarft = <0x1bf0 0x09 0x1b56 0x333 0x1b12 0x00 0x1b05 0x09 0x1c59 0xfc48 0xffff 0x00>;
		clk_path = <0x00>;
	};

	aocec {
		compatible = "amlogic, aocec-sm1";
		vendor_name = "Amlogic";
		output = <0x01>;
		arc_port_mask = <0x02>;
		reg-names = "ao_exit", "ao", "periphs";
		ee_cec;
		pinctrl-1 = <0x36>;
		product_desc = "SM1";
		status = "okay";
		interrupts = <0x00 0xcb 0x01 0x00 0xc7 0x01>;
		phandle = <0xec>;
		port_num = <0x01>;
		cec_osd_string = "AML_MBOX";
		cec_version = <0x05>;
		pinctrl-2 = <0x36>;
		vendor_id = <0x00>;
		device_name = "aocec";
		reg = <0xff80023c 0x04 0xff800000 0x400 0xff634400 0x70>;
		pinctrl-0 = <0x35>;
		interrupt-names = "hdmi_aocecb", "hdmi_aocec";
		pinctrl-names = "default", "hdmitx_aocecb", "cec_pin_sleep";
	};

	cpu_opp_table0 {
		compatible = "operating-points-v2";
		phandle = <0x0d>;
		opp-shared;

		opp06 {
			opp-microvolt = <0xc8320>;
			opp-hz = <0x00 0x53af5700>;
		};

		opp04 {
			opp-microvolt = "", "\f5";
			opp-hz = <0x00 0x3b9aca00>;
		};

		opp02 {
			opp-microvolt = <0xb98c0>;
			opp-hz = <0x00 0x1dcd6500>;
		};

		opp10 {
			opp-microvolt = <0xe7ef0>;
			opp-hz = <0x00 0x6b49d200>;
		};

		opp00 {
			opp-microvolt = <0xb98c0>;
			opp-hz = <0x00 0x5f5e100>;
		};

		opp09 {
			opp-microvolt = <0xdbba0>;
			opp-hz = <0x00 0x6590fa00>;
		};

		opp07 {
			opp-microvolt = <0xcaa30>;
			opp-hz = <0x00 0x59682f00>;
		};

		opp05 {
			opp-microvolt = <0xc5c10>;
			opp-hz = <0x00 0x47868c00>;
		};

		opp03 {
			opp-microvolt = <0xbe6e0>;
			opp-hz = <0x00 0x27c19cc0>;
		};

		opp11 {
			opp-microvolt = <0xf6950>;
			opp-hz = <0x00 0x71b9c500>;
		};

		opp01 {
			opp-microvolt = <0xb98c0>;
			opp-hz = <0x00 0xee6b280>;
		};

		opp08 {
			opp-microvolt = <0xd1f60>;
			opp-hz = <0x00 0x5fd82200>;
		};
	};

	usb3phy@ffe09080 {
		u3-ctrl-iso-shift = <0x12>;
		compatible = "amlogic, amlogic-new-usb3-v2";
		clocks = <0x02 0x18>;
		usb2-phy-reg-size = <0x80>;
		usb2-phy-reg = <0xffe09000>;
		default-host;
		clock-names = "pcie_refpll";
		portnum = <0x01>;
		status = "okay";
		interrupts = <0x00 0x10 0x04>;
		phandle = <0x13>;
		phy-reg = <0xff646000>;
		u3-hhi-mem-pd-shift = <0x1a>;
		reg = <0xffe09080 0x20 0xffd01008 0x100>;
		pwr-ctl = <0x01>;
		otg = <0x01>;
		u3-hhi-mem-pd-mask = <0x0f>;
		u3-ctrl-sleep-shift = <0x12>;
		phy-reg-size = <0x2000>;
	};

	jtag {
		compatible = "amlogic, jtag";
		select = "disable";
		pinctrl-1 = <0x17>;
		status = "okay";
		pinctrl-0 = <0x16>;
		pinctrl-names = "jtag_apao_pins", "jtag_apee_pins";
	};

	thermal-zones {

		ddr_thermal {
			thermal-sensors = <0x52 0x01>;
			polling-delay = <0x7d0>;
			polling-delay-passive = <0x3e8>;
			phandle = <0xfe>;
			sustainable-power = <0x582>;

			trips {

				trip-point@3 {
					hysteresis = <0x3e8>;
					temperature = <0x1adb0>;
					type = "critical";
					phandle = <0x102>;
				};

				trip-point@1 {
					hysteresis = <0x1388>;
					temperature = <0x124f8>;
					type = "passive";
					phandle = <0x100>;
				};

				trip-point@2 {
					hysteresis = <0x1388>;
					temperature = <0x14c08>;
					type = "hot";
					phandle = <0x101>;
				};

				trip-point@0 {
					hysteresis = <0x1388>;
					temperature = <0xea60>;
					type = "passive";
					phandle = <0xff>;
				};
			};
		};

		soc_thermal {
			thermal-sensors = <0x4c 0x00>;
			polling-delay = <0x3e8>;
			polling-delay-passive = <0x64>;
			phandle = <0xfa>;
			sustainable-power = <0x582>;

			trips {

				trip-point@3 {
					hysteresis = <0x3e8>;
					temperature = <0x1adb0>;
					type = "critical";
					phandle = <0xfd>;
				};

				trip-point@1 {
					hysteresis = <0x1388>;
					temperature = <0x124f8>;
					type = "passive";
					phandle = <0x4d>;
				};

				trip-point@2 {
					hysteresis = <0x1388>;
					temperature = <0x14c08>;
					type = "hot";
					phandle = <0xfc>;
				};

				trip-point@0 {
					hysteresis = <0x1388>;
					temperature = <0xea60>;
					type = "passive";
					phandle = <0xfb>;
				};
			};

			cooling-maps {

				cpufreq_cooling_map {
					trip = <0x4d>;
					contribution = <0x400>;
					cooling-device = <0x4e 0x00 0x04>;
				};

				gpucore_cooling_map {
					trip = <0x4d>;
					contribution = <0x400>;
					cooling-device = <0x51 0x00 0x02>;
				};

				cpucore_cooling_map {
					trip = <0x4d>;
					contribution = <0x400>;
					cooling-device = <0x4f 0x00 0x03>;
				};

				gpufreq_cooling_map {
					trip = <0x4d>;
					contribution = <0x400>;
					cooling-device = <0x50 0x00 0x03>;
				};
			};
		};
	};

	mhu@c883c400 {
		compatible = "amlogic, meson_mhu";
		#mbox-cells = <0x01>;
		interrupts = <0x00 0xd1 0x01 0x00 0xd2 0x01>;
		mbox-names = "cpu_to_scp_low", "cpu_to_scp_high";
		mboxes = <0x10 0x00 0x10 0x01>;
		phandle = <0x10>;
		reg = <0xff63c400 0x4c 0xfffe7000 0x800>;
	};

	usb2phy@ffe09000 {
		gpios = <0x14 0x16 0x00>;
		pll-setting-5 = <0x8000fff>;
		compatible = "amlogic, amlogic-new-usb2-v2";
		version = <0x02>;
		pll-setting-3 = <0xac5f69e5>;
		u2-hhi-mem-pd-shift = <0x1e>;
		u2-hhi-mem-pd-mask = <0x03>;
		pll-setting-1 = <0x9400414>;
		u2-ctrl-sleep-shift = <0x11>;
		pll-setting-8 = <0xe000c>;
		u2-ctrl-iso-shift = <0x11>;
		portnum = <0x02>;
		gpio-vbus-power = "GPIOH_5";
		pll-setting-6 = <0x78000>;
		status = "okay";
		pll-setting-4 = <0xfe18>;
		phandle = <0x12>;
		pll-setting-2 = <0x927e0000>;
		reg = <0xffe09000 0x80 0xffd01008 0x100 0xff636000 0x2000 0xff63a000 0x2000>;
		pwr-ctl = <0x01>;
		pll-setting-7 = <0xe0004>;
	};

	rdma {
		compatible = "amlogic, meson, rdma";
		dev_name = "amlogic-rdma";
		status = "okay";
		interrupts = <0x00 0x59 0x01>;
		interrupt-names = "rdma";
	};

	amlvideo2_0 {
		compatible = "amlogic, amlvideo2";
		amlvideo2_id = <0x00>;
		dev_name = "amlvideo2";
		cma_mode = <0x01>;
		status = "okay";
	};

	serial@ffd23000 {
		compatible = "amlogic, meson-uart";
		clocks = <0x15 0x02 0x3c>;
		fifosize = <0x40>;
		clock-names = "clk_uart", "clk_gate";
		status = "disabled";
		interrupts = <0x00 0x4b 0x01>;
		phandle = <0xe8>;
		reg = <0xffd23000 0x18>;
		pinctrl-0 = <0x2e>;
		pinctrl-names = "default";
	};

	sd@ffe05000 {
		cap-mmc-highspeed;
		pinctrl-5 = <0x3c 0x41>;
		compatible = "amlogic, meson-mmc-sm1";
		clocks = <0x02 0x34 0x02 0x6e 0x02 0x02 0x02 0x05 0x15>;
		pinctrl-3 = <0x3f 0x3d 0x40>;
		cap-sd-highspeed;
		pinctrl-1 = <0x3d>;
		clock-names = "core", "clkin0", "clkin1", "clkin2", "xtal";
		pinctrl-8 = <0x3f 0x40>;
		pinctrl-6 = <0x3f 0x40>;
		status = "okay";
		interrupts = <0x00 0xbe 0x01>;
		disable-wp;
		bus-width = <0x04>;
		pinctrl-4 = <0x3f 0x3e 0x40>;
		phandle = <0xf4>;
		pinctrl-2 = <0x3e>;
		reg = <0xffe05000 0x800>;
		pinctrl-0 = <0x3c>;
		pinctrl-9 = <0x42>;
		max-frequency = <0x5f5e100>;
		pinctrl-7 = <0x3c 0x41>;
		pinctrl-names = "sd_all_pins", "sd_clk_cmd_pins", "sd_1bit_pins", "sd_clk_cmd_uart_pins", "sd_1bit_uart_pins", "sd_to_ao_uart_pins", "ao_to_sd_uart_pins", "sd_to_ao_jtag_pins", "ao_to_sd_jtag_pins", "sd_all_pd_pins";

		sd {
			max_req_size = <0x20000>;
			jtag_pin = <0x14 0x2b 0x00>;
			gpio_dat3 = <0x14 0x2d 0x00>;
			f_min = <0x61a80>;
			card_type = <0x05>;
			f_max = <0x2faf080>;
			ocr_avail = <0x200080>;
			pinname = "sd";
			gpio_cd = <0x14 0x30 0x00>;
			caps = "MMC_CAP_4_BIT_DATA", "MMC_CAP_MMC_HIGHSPEED", "MMC_CAP_SD_HIGHSPEED";
		};
	};

	timer {
		compatible = "arm,armv7-timer";
		interrupts = <0x01 0x0d 0xff08 0x01 0x0e 0xff08 0x01 0x0b 0xff08 0x01 0x0a 0xff08>;
	};

	amdolby_vision {
		compatible = "amlogic, dolby_vision_sm1";
		dev_name = "aml_amdolby_vision_driver";
		status = "okay";
		tv_mode = <0x00>;
	};

	ethernet@ff3f0000 {
		analog_val = <0x20200000 0xc000 0x23>;
		pll_val = <0x9c0040a 0x927e0000 0xac5f49e5>;
		compatible = "amlogic, g12a-eth-dwmac", "snps,dwmac";
		clocks = <0x02 0x38>;
		reg-names = "eth_base", "eth_cfg", "eth_pll", "eth_reset";
		internal_phy = <0x00>;
		wol = <0x01>;
		clock-names = "ethclk81";
		status = "okay";
		interrupts = <0x00 0x08 0x01>;
		phandle = <0x94>;
		mc_val = <0x1621>;
		reg = <0xff3f0000 0x10000 0xff634540 0x08 0xff64c000 0xa0 0xffd01008 0x04>;
		pinctrl-0 = <0x11>;
		interrupt-names = "macirq";
		pinctrl-names = "external_eth_pins";
	};

	cpu_info {
		compatible = "amlogic, cpuinfo";
		cpuinfo_cmd = <0x82000044>;
		status = "okay";
	};

	dummy-charger {
		compatible = "amlogic, dummy-charger";
		status = "okay";
		phandle = <0x107>;
	};

	sdio@ffe03000 {
		cap-mmc-highspeed;
		compatible = "amlogic, meson-mmc-sm1";
		clocks = <0x02 0x33 0x02 0x6a 0x02 0x02 0x02 0x05 0x15>;
		cap-sd-highspeed;
		pinctrl-1 = <0x44>;
		clock-names = "core", "clkin0", "clkin1", "clkin2", "xtal";
		status = "okay";
		interrupts = <0x00 0xbd 0x04>;
		disable-wp;
		bus-width = <0x04>;
		phandle = <0xf5>;
		reg = <0xffe03000 0x800>;
		pinctrl-0 = <0x43>;
		max-frequency = <0x5f5e100>;
		pinctrl-names = "sdio_all_pins", "sdio_clk_cmd_pins";

		sdio {
			max_req_size = <0x20000>;
			f_min = <0x61a80>;
			card_type = <0x03>;
			f_max = <0xbebc200>;
			ocr_avail = <0x200080>;
			pinname = "sdio";
			caps = "MMC_CAP_4_BIT_DATA", "MMC_CAP_MMC_HIGHSPEED", "MMC_CAP_SD_HIGHSPEED", "MMC_CAP_NONREMOVABLE", "MMC_CAP_UHS_SDR12", "MMC_CAP_UHS_SDR25", "MMC_CAP_UHS_SDR50", "MMC_CAP_UHS_SDR104", "MMC_PM_KEEP_POWER", "MMC_CAP_SDIO_IRQ";
		};
	};

	deinterlace {
		compatible = "amlogic, deinterlace";
		clocks = <0x02 0x9b 0x02 0x9c>;
		nr10bit-support = <0x01>;
		nrds-enable = <0x01>;
		flag_cma = <0x01>;
		clock-range = <0x14e 0x29b>;
		pps-enable = <0x01>;
		clock-names = "vpu_clkb_tmp_composite", "vpu_clkb_composite";
		post-wr-support = <0x01>;
		status = "okay";
		interrupts = <0x00 0x2e 0x01 0x00 0x28 0x01>;
		memory-region = <0x6c>;
		interrupt-names = "pre_irq", "post_irq";
		buffer-size = <0x3e2c40>;
	};

	amhdmitx {
		compatible = "amlogic, amhdmitx";
		clocks = <0x02 0x55 0x02 0x4e 0x02 0x4f 0x02 0x95 0x02 0x8c>;
		dev_name = "amhdmitx";
		pinctrl-1 = <0x33 0x34>;
		clock-names = "venci_top_gate", "venci_0_gate", "venci_1_gate", "hdmi_vapb_clk", "hdmi_vpu_clk";
		status = "okay";
		vend-data = <0x30>;
		interrupts = <0x00 0x39 0x01>;
		phandle = <0xeb>;
		pinctrl-0 = <0x31 0x32>;
		ic_type = <0x0c>;
		interrupt-names = "hdmitx_hpd";
		pinctrl-names = "default", "hdmitx_i2c";

		vend_data {
			vendor_name = "Amlogic";
			product_desc = "MBox Meson Ref";
			phandle = <0x30>;
			vendor_id = <0x00>;
		};
	};

	meson-cooldev@0 {
		compatible = "amlogic, meson-cooldev";
		status = "okay";
		phandle = <0xf9>;
		device_name = "mcooldev";

		gpufreq_cool0 {
			phandle = <0x50>;
			#cooling-cells = <0x02>;
		};

		cpufreq_cool0 {
			phandle = <0x4e>;
			#cooling-cells = <0x02>;
		};

		gpucore_cool0 {
			phandle = <0x51>;
			#cooling-cells = <0x02>;
		};

		cooling_devices {

			cpucore_cool_cluster0 {
				node_name = "cpucore_cool0";
				device_type = "cpucore";
				dyn_coeff = <0x00>;
				cluster_id = <0x00>;
				gpu_pp = <0x02>;
				min_state = <0x01>;
			};

			gpufreq_cool {
				node_name = "gpufreq_cool0";
				device_type = "gpufreq";
				dyn_coeff = <0xd7>;
				cluster_id = <0x00>;
				gpu_pp = <0x02>;
				min_state = <0x190>;
			};

			cpufreq_cool_cluster0 {
				node_name = "cpufreq_cool0";
				device_type = "cpufreq";
				dyn_coeff = <0x7d>;
				cluster_id = <0x00>;
				gpu_pp = <0x02>;
				min_state = <0xf4240>;
			};

			gpucore_cool {
				node_name = "gpucore_cool0";
				device_type = "gpucore";
				dyn_coeff = <0x00>;
				cluster_id = <0x00>;
				gpu_pp = <0x02>;
				min_state = <0x01>;
			};
		};

		cpucore_cool0 {
			phandle = <0x4f>;
			#cooling-cells = <0x02>;
		};
	};

	ram-dump {
		compatible = "amlogic, ram_dump";
		reg-names = "PREG_STICKY_REG8";
		status = "okay";
		reg = <0xff6345e0 0x04>;
		store_device = "data";
	};

	dwc3@ff500000 {
		usb-phy = <0x12 0x13>;
		compatible = "synopsys, dwc3";
		clocks = <0x02 0x41>;
		clock-names = "dwc_general";
		clock-src = "usb3.0";
		status = "okay";
		interrupts = <0x00 0x1e 0x04>;
		phandle = <0xc3>;
		reg = <0xff500000 0x100000>;
		cpu-type = "gxl";
	};

	hevc_enc {
		compatible = "cnm, HevcEnc";
		dev_name = "HevcEnc";
		ranges;
		status = "okay";
		#address-cells = <0x01>;
		interrupts = <0x00 0xbb 0x01>;
		#size-cells = <0x01>;
		interrupt-names = "wave420l_irq";

		io_reg_base {
			reg = <0xff610000 0x4000>;
		};
	};

	bl40 {
		compatible = "amlogic, bl40-bootup";
		status = "okay";
		phandle = <0xc8>;
	};

	mesonstream {
		compatible = "amlogic, codec, streambuf";
		clocks = <0x02 0x40 0x02 0x39 0x02 0x43 0x02 0x22 0x02 0x0b 0x02 0xa5 0x02 0xae 0x02 0xb7 0x02 0xc0>;
		dev_name = "mesonstream";
		clock-names = "parser_top", "demux", "ahbarb0", "vdec", "clk_81", "clk_vdec_mux", "clk_hcodec_mux", "clk_hevc_mux", "clk_hevcb_mux";
		status = "okay";
	};

	auge_sound {
		compatible = "amlogic, g12a-sound-card";
		aml-audio-card,name = "AML-AUGESOUND";
		avout_mute-gpios = <0x64 0x02 0x00>;

		aml-audio-card,dai-link@0 {
			suffix-name = "alsaPORT-pcm";
			frame-master = <0x82>;
			bitclock-master = <0x82>;
			mclk-fs = <0x200>;
			format = "dsp_a";

			cpu {
				dai-tdm-slot-width = <0x20>;
				system-clock-frequency = <0x1770000>;
				dai-tdm-slot-tx-mask = <0x01 0x01 0x01 0x01 0x01 0x01 0x01 0x01>;
				phandle = <0x109>;
				sound-dai = <0x82>;
				dai-tdm-slot-rx-mask = <0x01 0x01 0x01 0x01 0x01 0x01 0x01 0x01>;
				dai-tdm-slot-num = <0x08>;
			};

			codec {
				phandle = <0x10a>;
				sound-dai = <0x83 0x83>;
			};
		};

		aml-audio-card,dai-link@7 {
			continuous-clock;
			suffix-name = "alsaPORT-loopback";
			mclk-fs = <0x100>;

			cpu {
				system-clock-frequency = <0xbb8000>;
				sound-dai = <0x8b>;
			};

			codec {
				sound-dai = <0x83>;
			};
		};

		aml-audio-card,dai-link@5 {
			continuous-clock;
			suffix-name = "alsaPORT-spdifb";
			mclk-fs = <0x80>;

			cpu {
				system-clock-frequency = <0x5dc000>;
				sound-dai = <0x89>;
			};

			codec {
				sound-dai = <0x83>;
			};
		};

		aml-audio-card,dai-link@3 {
			suffix-name = "alsaPORT-pdm";
			mclk-fs = <0x40>;

			cpu {
				sound-dai = <0x87>;
			};

			codec {
				sound-dai = <0x83>;
			};
		};

		aml-audio-card,dai-link@1 {
			suffix-name = "alsaPORT-i2s";
			frame-master = <0x84>;
			bitclock-master = <0x84>;
			mclk-fs = <0x100>;
			format = "i2s";

			cpu {
				dai-tdm-slot-width = <0x20>;
				system-clock-frequency = <0xbb8000>;
				dai-tdm-slot-tx-mask = <0x01 0x01>;
				sound-dai = <0x84>;
				dai-tdm-slot-rx-mask = <0x01 0x01>;
				dai-tdm-slot-num = <0x02>;
			};

			codec {
				phandle = <0x10b>;
				sound-dai = <0x83 0x83 0x85>;
			};
		};

		aml-audio-card,dai-link@6 {
			suffix-name = "alsaPORT-earc";
			mclk-fs = <0x100>;

			cpu {
				system-clock-frequency = <0xbb8000>;
				sound-dai = <0x8a>;
			};

			codec {
				sound-dai = <0x83>;
			};
		};

		aml-audio-card,dai-link@4 {
			suffix-name = "alsaPORT-spdif";
			mclk-fs = <0x80>;

			cpu {
				system-clock-frequency = <0x5dc000>;
				sound-dai = <0x88>;
			};

			codec {
				sound-dai = <0x83>;
			};
		};

		aml-audio-card,dai-link@2 {
			continuous-clock;
			suffix-name = "alsaPORT-i2s2hdmi";
			frame-master = <0x86>;
			bitclock-master = <0x86>;
			mclk-fs = <0x100>;
			format = "i2s";

			cpu {
				dai-tdm-slot-width = <0x20>;
				system-clock-frequency = <0xbb8000>;
				dai-tdm-slot-tx-mask = <0x01 0x01>;
				sound-dai = <0x86>;
				dai-tdm-slot-rx-mask = <0x01 0x01>;
				dai-tdm-slot-num = <0x02>;
			};

			codec {
				sound-dai = <0x83 0x83>;
			};
		};
	};

	picdec {
		compatible = "amlogic, picdec";
		dev_name = "picdec";
		status = "okay";
		memory-region = <0x6a>;
	};

	interrupt-controller@2c001000 {
		compatible = "arm,cortex-a15-gic", "arm,cortex-a9-gic";
		#interrupt-cells = <0x03>;
		#address-cells = <0x00>;
		interrupts = <0x01 0x09 0xf04>;
		phandle = <0x01>;
		reg = <0xffc01000 0x1000 0xffc02000 0x100>;
		interrupt-controller;
	};

	securitykey {
		compatible = "aml, securitykey";
		storage_status = <0x82000065>;
		storage_tell = <0x82000063>;
		storage_remove = <0x82000068>;
		storage_list = <0x82000067>;
		storage_size_func = <0x82000027>;
		storage_set_enctype = <0x8200006a>;
		storage_version = <0x8200006c>;
		storage_block_func = <0x82000025>;
		storage_in_func = <0x82000023>;
		storage_out_func = <0x82000024>;
		storage_read = <0x82000061>;
		storage_write = <0x82000062>;
		storage_query = <0x82000060>;
		storage_verify = <0x82000064>;
		storage_get_enctype = <0x8200006b>;
	};

	nfc@0 {
		compatible = "amlogic, aml_mtd_nand";
		clocks = <0x02 0x35 0x02 0x72>;
		dev_name = "mtdnand";
		plat-names = "bootloader", "nandnormal";
		pinctrl-1 = <0x45>;
		plat-part-0 = <0x47>;
		clock-names = "core", "clkin";
		nand_clk_ctrl = <0xffe07000>;
		status = "disabled";
		interrupts = <0x00 0x22 0x01>;
		phandle = <0xf6>;
		pinctrl-2 = <0x46>;
		reg = <0xffe07800 0x200>;
		plat-part-1 = <0x48>;
		pinctrl-0 = <0x45>;
		device_id = <0x00>;
		fip_size = <0x200000>;
		plat-num = <0x02>;
		bl_mode = <0x01>;
		fip_copies = <0x04>;
		pinctrl-names = "nand_rb_mod", "nand_norb_mod", "nand_cs_only";

		nandnormal {
			t_rhoh = <0x0f>;
			plane_mode = "twoplane";
			rb_detect = <0x01>;
			partition = <0x49>;
			t_rea = <0x14>;
			phandle = <0x48>;
			busy_pad = "rb0";
			part_num = <0x03>;
			timming_mode = "mode5";
			chip_num = <0x02>;
			enable_pad = "ce0";
			bch_mode = "bch8_1k";
		};

		bootloader {
			t_rhoh = <0x0f>;
			rb_detect = <0x01>;
			t_rea = <0x14>;
			phandle = <0x47>;
			busy_pad = "rb0";
			part_num = <0x00>;
			timming_mode = "mode5";
			chip_num = <0x01>;
			enable_pad = "ce0";
			bch_mode = "bch8_1k";
		};

		nand_partition {
			phandle = <0x49>;

			logo {
				offset = <0x00 0x00>;
				size = <0x00 0x200000>;
			};

			system {
				offset = <0x00 0x00>;
				size = <0x00 0x4000000>;
			};

			tpl {
				offset = <0x00 0x00>;
				size = <0x00 0x00>;
			};

			data {
				offset = <0xffffffff 0xffffffff>;
				size = <0x00 0x00>;
			};

			recovery {
				offset = <0x00 0x00>;
				size = <0x00 0x1000000>;
			};

			boot {
				offset = <0x00 0x00>;
				size = <0x00 0x1000000>;
			};
		};
	};

	vdin1 {
		compatible = "amlogic, vdin";
		tv_bit_mode = <0x01>;
		dev_name = "vdin1";
		flag_cma = <0x00>;
		status = "disabled";
		interrupts = <0x00 0x55 0x01>;
		phandle = <0xee>;
		rdma-irq = <0x04>;
		vdin_id = <0x01>;
		reserve-iomap = "true";
	};

	canvas {
		compatible = "amlogic, meson, canvas";
		dev_name = "amlogic-canvas";
		status = "okay";
		phandle = <0xef>;
		reg = <0xff638000 0x2000>;
	};

	locker {
		compatible = "amlogic, audiolocker";
		clocks = <0x1c 0x2d 0x1c 0x2e 0x1c 0x27 0x1c 0x28 0x02 0x0d 0x02 0x0e>;
		clock-names = "lock_out", "lock_in", "out_src", "in_src", "out_calc", "in_ref";
		status = "disabled";
		interrupts = <0x00 0x01 0x01>;
		phandle = <0x10c>;
		dividor = <0x31>;
		interrupt-names = "irq";
		frequency = <0x2ebae40>;
	};

	cpus {
		#address-cells = <0x01>;
		#size-cells = <0x00>;
		phandle = <0x91>;

		cpu@3 {
			compatible = "arm,cortex-a53", "arm,armv8";
			clocks = <0x02 0x17 0x02 0x16 0x02 0x00 0x02 0xf8 0x02 0xf7>;
			cpu-idle-states = <0x0c>;
			device_type = "cpu";
			clock-names = "core_clk", "low_freq_clk_parent", "high_freq_clk_parent", "dsu_clk", "dsu_pre_parent";
			voltage-tolerance = <0x00>;
			enable-method = "psci";
			cpu-supply = <0x0e>;
			phandle = <0x0b>;
			operating-points-v2 = <0x0d>;
			reg = <0x03>;
			clock-latency = <0xc350>;
		};

		idle-states {
			entry-method = "arm,psci-0.2";

			cpu-sleep-0 {
				compatible = "arm,idle-state";
				arm,psci-suspend-param = <0x10000>;
				phandle = <0x0c>;
				exit-latency-us = <0x1388>;
				entry-latency-us = <0xfa0>;
				local-timer-stop;
				min-residency-us = <0x2710>;
			};
		};

		cpu@1 {
			compatible = "arm,cortex-a53", "arm,armv8";
			clocks = <0x02 0x17 0x02 0x16 0x02 0x00 0x02 0xf8 0x02 0xf7>;
			cpu-idle-states = <0x0c>;
			device_type = "cpu";
			clock-names = "core_clk", "low_freq_clk_parent", "high_freq_clk_parent", "dsu_clk", "dsu_pre_parent";
			voltage-tolerance = <0x00>;
			enable-method = "psci";
			cpu-supply = <0x0e>;
			phandle = <0x09>;
			operating-points-v2 = <0x0d>;
			reg = <0x01>;
			clock-latency = <0xc350>;
		};

		cpu-map {

			cluster0 {
				phandle = <0x92>;

				core0 {
					cpu = <0x08>;
				};

				core3 {
					cpu = <0x0b>;
				};

				core1 {
					cpu = <0x09>;
				};

				core2 {
					cpu = <0x0a>;
				};
			};
		};

		cpu@2 {
			compatible = "arm,cortex-a53", "arm,armv8";
			clocks = <0x02 0x17 0x02 0x16 0x02 0x00 0x02 0xf8 0x02 0xf7>;
			cpu-idle-states = <0x0c>;
			device_type = "cpu";
			clock-names = "core_clk", "low_freq_clk_parent", "high_freq_clk_parent", "dsu_clk", "dsu_pre_parent";
			voltage-tolerance = <0x00>;
			enable-method = "psci";
			cpu-supply = <0x0e>;
			phandle = <0x0a>;
			operating-points-v2 = <0x0d>;
			reg = <0x02>;
			clock-latency = <0xc350>;
		};

		cpu@0 {
			compatible = "arm,cortex-a53", "arm,armv8";
			clocks = <0x02 0x17 0x02 0x16 0x02 0x00 0x02 0xf8 0x02 0xf7>;
			cpu-idle-states = <0x0c>;
			device_type = "cpu";
			clock-names = "core_clk", "low_freq_clk_parent", "high_freq_clk_parent", "dsu_clk", "dsu_pre_parent";
			voltage-tolerance = <0x00>;
			enable-method = "psci";
			cpu-supply = <0x0e>;
			phandle = <0x08>;
			operating-points-v2 = <0x0d>;
			reg = <0x00>;
			clock-latency = <0xc350>;
		};
	};

	saradc {
		compatible = "amlogic,meson-g12a-saradc";
		clocks = <0x15 0x02 0x105>;
		#io-channel-cells = <0x01>;
		clock-names = "xtal", "saradc_clk";
		status = "disabled";
		interrupts = <0x00 0xc8 0x01>;
		phandle = <0xc6>;
		reg = <0xff809000 0x48>;
	};

	power_ctrl@ff8000e8 {
		compatible = "amlogic, sm1-powerctrl";
		phandle = <0xc7>;
		reg = <0xff8000e8 0x10 0xff63c100 0x10>;
	};

	t9015 {
		tocodec_inout = <0x01>;
		compatible = "amlogic, aml_codec_T9015";
		#sound-dai-cells = <0x00>;
		ch0_sel = <0x00>;
		status = "okay";
		ch1_sel = <0x01>;
		phandle = <0x85>;
		reg = <0xff632000 0x2000>;
		tdmout_index = <0x01>;
		is_auge_used = <0x01>;
	};

	memory@00000000 {
		device_type = "memory";
		linux,usable-memory = <0x00 0xf5700000>;
		phandle = <0x104>;
		reg = <0x00 0xed800000>;
	};

	timer_bc {
		clockevent-rating = <0x12c>;
		compatible = "arm, meson-bc-timer";
		bit_enable = <0x10>;
		timer_name = "Meson TimerF";
		clockevent-features = <0x23>;
		bit_mode = <0x0c>;
		interrupts = <0x00 0x3c 0x01>;
		reg = <0xffd0f190 0x04 0xffd0f194 0x04>;
		bit_resolution = <0x00>;
		clockevent-shift = <0x14>;
	};

	efuse {
		compatible = "amlogic, efuse";
		clocks = <0x02 0x61>;
		read_cmd = <0x82000030>;
		get_max_cmd = <0x82000033>;
		clock-names = "efuse_clk";
		write_cmd = <0x82000031>;
		status = "disabled";
		key = <0x4b>;
		phandle = <0xf8>;
	};

	ppmgr {
		compatible = "amlogic, ppmgr";
		dev_name = "ppmgr";
		status = "okay";
		memory-region = <0x6b>;
	};

	pinctrl@ff634480 {
		compatible = "amlogic,meson-g12a-periphs-pinctrl";
		ranges;
		#address-cells = <0x01>;
		#size-cells = <0x01>;
		phandle = <0xa3>;

		pwm_d_pins2 {
			phandle = <0xba>;

			mux {
				groups = "pwm_d_x6";
				function = "pwm_d";
			};
		};

		pdmin {
			phandle = <0x27>;

			mux {
				groups = "pdm_din0_a", "pdm_din2_a", "pdm_dclk_a";
				function = "pdm";
			};
		};

		spicc1_pins {
			phandle = <0xbf>;

			mux {
				drive-strength = <0x01>;
				groups = "spi1_mosi", "spi1_miso", "spi1_clk";
				function = "spi1";
			};
		};

		pwm_e {
			phandle = <0x65>;

			mux {
				groups = "pwm_e";
				function = "pwm_e";
			};
		};

		ee_cecb {
			phandle = <0x36>;

			mux {
				groups = "cec_ao_b_ee";
				function = "cec_ao_ee";
			};
		};

		ao_to_sd_uart_pins {
			phandle = <0x40>;

			mux {
				groups = "uart_ao_tx_a_c3", "uart_ao_rx_a_c2";
				function = "uart_ao_a_ee";
				input-enable;
				bias-pull-up;
			};
		};

		sdio_x_clr_pins {
			phandle = <0xa9>;

			mux1 {
				output-low;
				groups = "GPIOX_4";
				function = "gpio_periphs";
			};

			mux {
				output-low;
				groups = "GPIOV_0";
				function = "gpio_periphs";
				bias-pull-up;
			};
		};

		emmc_conf_pull_up {
			phandle = <0x3a>;

			mux {
				drive-strength = <0x03>;
				groups = "emmc_nand_d7", "emmc_nand_d6", "emmc_nand_d5", "emmc_nand_d4", "emmc_nand_d3", "emmc_nand_d2", "emmc_nand_d1", "emmc_nand_d0", "emmc_clk", "emmc_cmd";
				function = "emmc";
				input-enable;
				bias-pull-up;
			};
		};

		i2c0_pins2 {
			phandle = <0xab>;

			mux {
				drive-strength = <0x02>;
				groups = "i2c0_sda_z0", "i2c0_sck_z1";
				function = "i2c0";
			};
		};

		pwm_c_pins3 {
			phandle = <0xb8>;

			mux {
				groups = "pwm_c_x8";
				function = "pwm_c";
			};
		};

		sdio_x_all_pins {
			phandle = <0xa7>;

			mux1 {
				drive-strength = <0x03>;
				groups = "GPIOX_4";
				function = "gpio_periphs";
				bias-pull-up;
				output-high;
			};

			mux {
				drive-strength = <0x03>;
				groups = "GPIOX_0", "GPIOX_1", "GPIOX_2", "GPIOX_3", "GPIOX_5";
				function = "gpio_periphs";
				input-enable;
				bias-pull-up;
			};
		};

		sdio_clk_cmd_pins {
			phandle = <0x44>;

			mux {
				drive-strength = <0x03>;
				groups = "sdio_clk", "sdio_cmd";
				function = "sdio";
				input-enable;
				bias-pull-up;
			};
		};

		i2c3_pins2 {
			phandle = <0x18>;

			mux {
				drive-strength = <0x02>;
				groups = "i2c3_sda_a", "i2c3_sck_a";
				function = "i2c3";
			};
		};

		tdmout_b {
			phandle = <0x20>;

			mux {
				drive-strength = <0x02>;
				groups = "tdmb_sclk", "tdmb_fs", "tdmb_dout0";
				function = "tdmb_out";
			};
		};

		spdifout {
			phandle = <0x25>;

			mux {
				groups = "spdif_out_h";
				function = "spdif_out";
			};
		};

		external_eth_pins {
			phandle = <0x11>;

			mux {
				drive-strength = <0x03>;
				groups = "eth_mdio", "eth_mdc", "eth_rgmii_rx_clk", "eth_rx_dv", "eth_rxd0", "eth_rxd1", "eth_rxd2_rgmii", "eth_rxd3_rgmii", "eth_rgmii_tx_clk", "eth_txen", "eth_txd0", "eth_txd1", "eth_txd2_rgmii", "eth_txd3_rgmii";
				function = "eth";
			};
		};

		internal_gpio_pins {
			phandle = <0xc1>;

			mux {
				bias-disable;
				groups = "GPIOZ_14", "GPIOZ_15";
				function = "gpio_periphs";
				input-enable;
			};
		};

		pwm_c_pins1 {
			phandle = <0xb6>;

			mux {
				groups = "pwm_c_c4";
				function = "pwm_c";
			};
		};

		emmc_conf_pull_done {
			phandle = <0x3b>;

			mux {
				drive-strength = <0x03>;
				groups = "emmc_nand_ds";
				function = "emmc";
				bias-pull-down;
				input-enable;
			};
		};

		jtag_apee_pin {
			phandle = <0x17>;

			mux {
				groups = "jtag_b_tdi", "jtag_b_tdo", "jtag_b_clk", "jtag_b_tms";
				function = "jtag_b";
			};
		};

		i2c2_pins3 {
			phandle = <0xb2>;

			mux {
				drive-strength = <0x02>;
				groups = "i2c2_sda_z10", "i2c2_sck_z11";
				function = "i2c2";
			};
		};

		pwm_a {
			phandle = <0xb3>;

			mux {
				groups = "pwm_a";
				function = "pwm_a";
			};
		};

		pwm_f_pins1 {
			phandle = <0xbb>;

			mux {
				groups = "pwm_f_x";
				function = "pwm_f";
			};
		};

		pwm_b_pins2 {
			phandle = <0xb5>;

			mux {
				groups = "pwm_b_x19";
				function = "pwm_b";
			};
		};

		i2c2_pins1 {
			phandle = <0xb0>;

			mux {
				drive-strength = <0x02>;
				groups = "i2c2_sda_x", "i2c2_sck_x";
				function = "i2c2";
			};
		};

		tdmin_c {
			phandle = <0x24>;

			mux {
				groups = "tdmc_din0_a";
				function = "tdmc_in";
			};
		};

		i2c1_pins2 {
			phandle = <0xae>;

			mux {
				drive-strength = <0x02>;
				groups = "i2c1_sda_h2", "i2c1_sck_h3";
				function = "i2c1";
			};
		};

		sd_clr_all_pins {
			phandle = <0xa4>;

			mux1 {
				output-low;
				groups = "GPIOC_4";
				function = "gpio_periphs";
			};

			mux {
				groups = "GPIOC_0", "GPIOC_1", "GPIOC_2", "GPIOC_3", "GPIOC_5";
				function = "gpio_periphs";
				output-high;
			};
		};

		nand_cs {
			phandle = <0x46>;

			mux {
				groups = "nand_ce0";
				function = "nand";
			};
		};

		all_nand_pins {
			phandle = <0x45>;

			mux {
				groups = "emmc_nand_d0", "emmc_nand_d1", "emmc_nand_d2", "emmc_nand_d3", "emmc_nand_d4", "emmc_nand_d5", "emmc_nand_d6", "emmc_nand_d7", "nand_ce0", "nand_ale", "nand_cle", "nand_wen_clk", "nand_ren_wr", "nand_rb0";
				function = "nand";
				input-enable;
			};
		};

		tdmc_mclk {
			phandle = <0x22>;

			mux {
				groups = "mclk1_a";
				function = "mclk1";
			};
		};

		tdmin_a {
			phandle = <0x1e>;

			mux {
				groups = "tdma_din1";
				function = "tdma_in";
			};
		};

		sd_all_pins {
			phandle = <0x3c>;

			mux1 {
				drive-strength = <0x03>;
				groups = "sdcard_clk_c";
				function = "sdcard";
				bias-pull-up;
				output-high;
			};

			mux {
				drive-strength = <0x03>;
				groups = "sdcard_d0_c", "sdcard_d1_c", "sdcard_d2_c", "sdcard_d3_c", "sdcard_cmd_c";
				function = "sdcard";
				input-enable;
				bias-pull-up;
			};
		};

		i2c0_pins3 {
			phandle = <0xac>;

			mux {
				drive-strength = <0x02>;
				groups = "i2c0_sda_z7", "i2c0_sck_z8";
				function = "i2c0";
			};
		};

		pwm_d_pins1 {
			phandle = <0xb9>;

			mux {
				groups = "pwm_d_x3";
				function = "pwm_d";
			};
		};

		sd_all_pd_pins {
			phandle = <0x42>;

			mux {
				output-low;
				groups = "GPIOC_0", "GPIOC_1", "GPIOC_2", "GPIOC_3", "GPIOC_4", "GPIOC_5";
				function = "gpio_periphs";
				bias-pull-down;
			};
		};

		tdmout_c {
			phandle = <0x23>;

			mux {
				groups = "tdmc_sclk_a", "tdmc_fs_a", "tdmc_dout0_a";
				function = "tdmc_out";
			};
		};

		ee_ceca {
			phandle = <0x35>;

			mux {
				groups = "cec_ao_a_ee";
				function = "cec_ao_ee";
			};
		};

		spicc0_pins_x {
			phandle = <0xbd>;

			mux {
				drive-strength = <0x01>;
				groups = "spi0_mosi_x", "spi0_miso_x", "spi0_clk_x";
				function = "spi0";
			};
		};

		internal_eth_pins {
			phandle = <0xc0>;

			mux {
				groups = "eth_link_led", "eth_act_led";
				function = "eth";
			};
		};

		i2c0_pins1 {
			phandle = <0xaa>;

			mux {
				drive-strength = <0x02>;
				groups = "i2c0_sda_c", "i2c0_sck_c";
				function = "i2c0";
			};
		};

		sdio_x_en_pins {
			phandle = <0xa8>;

			mux {
				groups = "sdio_dummy";
				function = "sdio";
				bias-pull-up;
				output-high;
			};
		};

		hdmitx_ddc {
			phandle = <0x32>;

			mux {
				bias-disable;
				drive-strength = <0x03>;
				groups = "hdmitx_sda", "hdmitx_sck";
				function = "hdmitx";
			};
		};

		pwm_c_pins2 {
			phandle = <0xb7>;

			mux {
				groups = "pwm_c_x5";
				function = "pwm_c";
			};
		};

		sd_clk_cmd_pins {
			phandle = <0x3d>;

			mux1 {
				drive-strength = <0x03>;
				groups = "sdcard_clk_c";
				function = "sdcard";
				bias-pull-up;
				output-high;
			};

			mux {
				drive-strength = <0x03>;
				groups = "sdcard_cmd_c";
				function = "sdcard";
				input-enable;
				bias-pull-up;
			};
		};

		tdmb_mclk {
			phandle = <0x1f>;

			mux {
				drive-strength = <0x02>;
				groups = "mclk0_a";
				function = "mclk0";
			};
		};

		i2c3_pins1 {
			phandle = <0x34>;

			mux {
				drive-strength = <0x02>;
				groups = "i2c3_sda_h", "i2c3_sck_h";
				function = "i2c3";
			};
		};

		c_uart {
			phandle = <0x2f>;

			mux {
				groups = "uart_tx_c", "uart_rx_c";
				function = "uart_c";
			};
		};

		tdmout_a {
			phandle = <0x1d>;

			mux {
				groups = "tdma_sclk", "tdma_fs", "tdma_dout0";
				function = "tdma_out";
			};
		};

		pwm_f_pins2 {
			phandle = <0xbc>;

			mux {
				groups = "pwm_f_h";
				function = "pwm_f";
			};
		};

		sd_1bit_pins {
			phandle = <0x3e>;

			mux1 {
				drive-strength = <0x03>;
				groups = "sdcard_clk_c";
				function = "sdcard";
				bias-pull-up;
				output-high;
			};

			mux {
				drive-strength = <0x03>;
				groups = "sdcard_d0_c", "sdcard_cmd_c";
				function = "sdcard";
				input-enable;
				bias-pull-up;
			};
		};

		spicc0_pins_c {
			phandle = <0xbe>;

			mux {
				drive-strength = <0x01>;
				groups = "spi0_mosi_c", "spi0_miso_c", "spi0_ss0_c", "spi0_clk_c";
				function = "spi0";
			};
		};

		i2c2_pins2 {
			phandle = <0xb1>;

			mux {
				drive-strength = <0x02>;
				groups = "i2c2_sda_z", "i2c2_sck_z";
				function = "i2c2";
			};
		};

		b_uart {
			phandle = <0x2e>;

			mux {
				groups = "uart_tx_b", "uart_rx_b";
				function = "uart_b";
			};
		};

		pwm_b_pins1 {
			phandle = <0xb4>;

			mux {
				groups = "pwm_b_x7";
				function = "pwm_b";
			};
		};

		i2c1_pins3 {
			phandle = <0xaf>;

			mux {
				drive-strength = <0x02>;
				groups = "i2c1_sda_h6", "i2c1_sck_h7";
				function = "i2c1";
			};
		};

		sdio_all_pins {
			phandle = <0x43>;

			mux {
				drive-strength = <0x03>;
				groups = "sdio_d0", "sdio_d1", "sdio_d2", "sdio_d3", "sdio_clk", "sdio_cmd";
				function = "sdio";
				input-enable;
				bias-pull-up;
			};
		};

		sd_clr_noall_pins {
			phandle = <0xa5>;

			mux {
				groups = "GPIOC_0", "GPIOC_1", "GPIOC_4", "GPIOC_5";
				function = "gpio_periphs";
				output-high;
			};
		};

		spdifout_a_mute {
			phandle = <0x26>;

			mux {
				groups = "GPIOH_4";
				function = "gpio_periphs";
			};
		};

		sdio_x_clk_cmd_pins {
			phandle = <0xa6>;

			mux1 {
				drive-strength = <0x03>;
				groups = "GPIOX_4";
				function = "gpio_periphs";
				bias-pull-up;
				output-high;
			};

			mux {
				drive-strength = <0x03>;
				groups = "GPIOX_5";
				function = "gpio_periphs";
				input-enable;
				bias-pull-up;
			};
		};

		banks@ff6346c0 {
			reg-names = "mux", "pull", "pull-enable", "gpio", "drive-strength";
			gpio-controller;
			phandle = <0x14>;
			reg = <0xff6346c0 0x40 0xff6344e8 0x18 0xff634520 0x18 0xff634440 0x4c 0xff634740 0x1c>;
			#gpio-cells = <0x02>;
		};

		tdmin_b {
			phandle = <0x21>;

			mux {
				drive-strength = <0x02>;
				groups = "tdmb_din1";
				function = "tdmb_in";
			};
		};

		hdmitx_hpd {
			phandle = <0x31>;

			mux {
				bias-disable;
				groups = "hdmitx_hpd_in";
				function = "hdmitx";
			};
		};

		emmc_clk_cmd_pins {
			phandle = <0x39>;

			mux {
				drive-strength = <0x03>;
				groups = "emmc_clk", "emmc_cmd";
				function = "emmc";
				input-enable;
				bias-pull-up;
			};
		};

		i2c1_pins1 {
			phandle = <0xad>;

			mux {
				drive-strength = <0x02>;
				groups = "i2c1_sda_x", "i2c1_sck_x";
				function = "i2c1";
			};
		};

		a_uart {
			phandle = <0x2d>;

			mux {
				groups = "uart_tx_a", "uart_rx_a", "uart_cts_a", "uart_rts_a";
				function = "uart_a";
			};
		};

		hdmitx_hpd_gpio {
			phandle = <0x33>;

			mux {
				bias-disable;
				groups = "GPIOH_1";
				function = "gpio_periphs";
			};
		};
	};

	rtc {
		compatible = "amlogic, aml_vrtc";
		alarm_reg_addr = <0xff8000a8>;
		timer_e_addr = <0xffd0f188>;
		status = "okay";
		init_date = "2015/01/01";
	};

	serial@ffd22000 {
		compatible = "amlogic, meson-uart";
		clocks = <0x15 0x02 0x3c>;
		fifosize = <0x40>;
		clock-names = "clk_uart", "clk_gate";
		status = "disabled";
		interrupts = <0x00 0x5d 0x01>;
		phandle = <0xe9>;
		reg = <0xffd22000 0x18>;
		pinctrl-0 = <0x2f>;
		pinctrl-names = "default";
	};

	ge2d {
		compatible = "amlogic, ge2d-sm1";
		clocks = <0x02 0x95 0x02 0x3d 0x02 0x96>;
		dev_name = "ge2d";
		clock-names = "clk_vapb_0", "clk_ge2d", "clk_ge2d_gate";
		status = "okay";
		interrupts = <0x00 0x92 0x01>;
		reg = <0xff940000 0x10000>;
		interrupt-names = "ge2d";
	};

	emmc@ffe07000 {
		cap-mmc-highspeed;
		compatible = "amlogic, meson-mmc-sm1";
		clocks = <0x02 0x35 0x02 0x72 0x02 0x02 0x02 0x20 0x15>;
		cap-sd-highspeed;
		pinctrl-1 = <0x3a 0x3b>;
		clock-names = "core", "clkin0", "clkin1", "clkin2", "xtal";
		status = "okay";
		interrupts = <0x00 0xbf 0x01>;
		disable-wp;
		bus-width = <0x08>;
		phandle = <0xf3>;
		reg = <0xffe07000 0x800>;
		pinctrl-0 = <0x39>;
		non-removable;
		max-frequency = <0xbebc200>;
		pinctrl-names = "emmc_clk_cmd_pins", "emmc_all_pins";

		emmc {
			max_req_size = <0x20000>;
			caps2 = "MMC_CAP2_HS200";
			gpio_dat3 = <0x14 0x1d 0x00>;
			f_min = <0x61a80>;
			card_type = <0x01>;
			f_max = <0x8f0d180>;
			ocr_avail = <0x200080>;
			hw_reset = <0x14 0x26 0x00>;
			co_phase = <0x03>;
			tx_delay = <0x00>;
			pinname = "emmc";
			caps = "MMC_CAP_8_BIT_DATA", "MMC_CAP_MMC_HIGHSPEED", "MMC_CAP_SD_HIGHSPEED", "MMC_CAP_NONREMOVABLE", "MMC_CAP_HW_RESET", "MMC_CAP_ERASE", "MMC_CAP_CMD23", "MMC_CAP_DRIVER_TYPE_D";
		};
	};

	vout2 {
		compatible = "amlogic, vout2";
		clocks = <0x02 0xc4 0x02 0xc9>;
		dev_name = "vout";
		clock-names = "vpu_clkc0", "vpu_clkc";
		status = "okay";
	};
};
